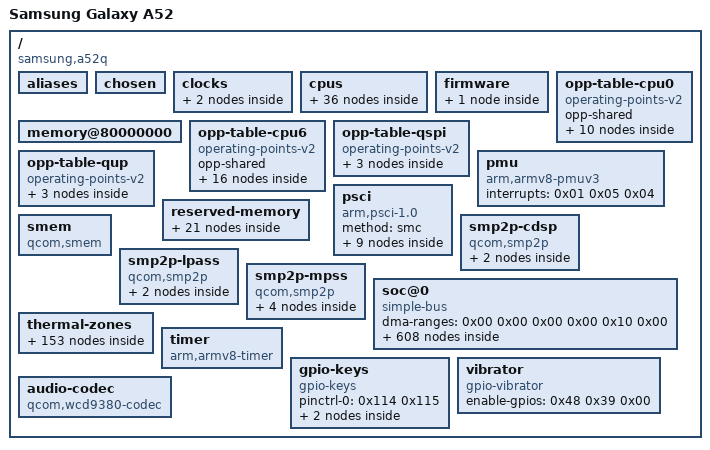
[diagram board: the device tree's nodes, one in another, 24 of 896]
/dts-v1/;

/ {
	interrupt-parent = <0x01>;
	#address-cells = <0x02>;
	#size-cells = <0x02>;
	chassis-type = "handset";
	qcom,msm-id = <0x1bb 0x00>;
	model = "Samsung Galaxy A52";
	compatible = "samsung,a52q", "qcom,sm7125";
	qcom,board-id = <0x22 0x06>;

	aliases {
		mmc1 = "/soc@0/mmc@7c4000";
		mmc2 = "/soc@0/mmc@8804000";
		i2c0 = "/soc@0/geniqup@8c0000/i2c@880000";
		i2c1 = "/soc@0/geniqup@8c0000/i2c@884000";
		i2c2 = "/soc@0/geniqup@8c0000/i2c@888000";
		i2c3 = "/soc@0/geniqup@8c0000/i2c@88c000";
		i2c4 = "/soc@0/geniqup@8c0000/i2c@890000";
		i2c5 = "/soc@0/geniqup@8c0000/i2c@894000";
		i2c6 = "/soc@0/geniqup@ac0000/i2c@a80000";
		i2c7 = "/soc@0/geniqup@ac0000/i2c@a84000";
		i2c8 = "/soc@0/geniqup@ac0000/i2c@a88000";
		i2c9 = "/soc@0/geniqup@ac0000/i2c@a8c000";
		i2c10 = "/soc@0/geniqup@ac0000/i2c@a90000";
		i2c11 = "/soc@0/geniqup@ac0000/i2c@a94000";
		spi0 = "/soc@0/geniqup@8c0000/spi@880000";
		spi1 = "/soc@0/geniqup@8c0000/spi@884000";
		spi3 = "/soc@0/geniqup@8c0000/spi@88c000";
		spi5 = "/soc@0/geniqup@8c0000/spi@894000";
		spi6 = "/soc@0/geniqup@ac0000/spi@a80000";
		spi8 = "/soc@0/geniqup@ac0000/spi@a88000";
		spi10 = "/soc@0/geniqup@ac0000/spi@a90000";
		spi11 = "/soc@0/geniqup@ac0000/spi@a94000";
		bluetooth0 = "/soc@0/geniqup@8c0000/serial@88c000/bluetooth";
		hsuart0 = "/soc@0/geniqup@8c0000/serial@88c000";
		i2c18 = "/soc@0/i2c-18";
		wifi0 = "/soc@0/wifi@18800000";
	};

	chosen {
		linux,initrd-end = <0x00 0xa91fea74>;
		linux,initrd-start = <0x00 0xa8ac4000>;
		kaslr-seed = <0x00 0x00>;
		bootargs = "console=null  pmos_boot_uuid=f75bd1ed-f519-480b-bffc-14573b47cbfd pmos_root_uuid=bdbc92a1-11d9-4b12-ba1a-d4a6c2b9d2fc pmos_rootfsopts=defaults androidboot.verifiedbootstate=orange androidboot.keymaster=1  androidboot.ulcnt=1  androidboot.bootdevice=1d84000.ufshc androidboot.fstab_suffix=default androidboot.boot_devices=soc/1d84000.ufshc androidboot.serialno=R58R31VW3YP androidboot.baseband=msm msm_drm.dsi_display0=ss_dsi_panel_S6E3FC3_AMS646YD04_FHD: lcd_id=0x80000A window_color= androidboot.dtb_idx=-1347440721 androidboot.sec_atd.tty=/dev/ttyHS8 androidboot.revision=8 androidboot.subpcb=3 androidboot.ap_serial=0xB2266249 ccic_info=1 fg_reset=0 sec_log=0x200000@0xB4900000 sec_dbg=0x1FF000@0xB4700000 androidboot.debug_level=0x4f4c sec_debug.enable=0 sec_debug.enable_user=0 msm_rtb.enable=0 androidboot.cp_debug_level=0x55FF sec_debug.enable_cp_debug=0 softdog.soft_margin=100 softdog.soft_panic=1 androidboot.cp_reserved_mem=off androidboot.reserve_mem_region=0x0 androidboot.force_upload=0x0 androidboot.upload_offset=9438196 sec_debug.dump_sink=0x0 signoff=0x7277 androidboot.boot_recovery=0 androidboot.carrierid.param.offset=9437644 androidboot.carrierid=EUX androidboot.sales.param.offset=9437648 androidboot.sales_code=EUX androidboot.prototype.param.offset=9437660 androidboot.im.param.offset=9437232 androidboot.me.param.offset=9437312 androidboot.sn.param.offset=9437392 androidboot.pr.param.offset=9437472 androidboot.sku.param.offset=9437552 androidboot.kg=0x1 androidboot.kg.bit=00 androidboot.kg.ap=AAAA00000000000000000000B2266249 androidboot.fastbootd=false androidboot.warranty_bit=1 androidboot.wb.hs=E02 androidboot.wb.snapQB=64747451R androidboot.ucs_mode=0 androidboot.swp_config=0 androidboot.rp=6 androidboot.svb.ver=SVB1.0 androidboot.em.did=207010B226624911 androidboot.em.model=SM-A525F androidboot.em.status=0x0 androidboot.sb.debug0=0x0 androidboot.em.rdx_dump=false androidboot.bootloader=A525FXXU6FXD2 afc_disable=0x31 sapa=0 androidboot.hdm_status=NONE androidboot.dram_info=01,07,01,6G androidboot.usrf=9438192 factory_mode=0 androidboot.product.model=SM-A525F androidboot.hardware.sku=unknown";
	};

	clocks {

		xo-board {
			compatible = "fixed-clock";
			clock-frequency = <0x249f000>;
			#clock-cells = <0x00>;
			phandle = <0xd7>;
		};

		sleep-clk {
			compatible = "fixed-clock";
			clock-frequency = <0x7ffc>;
			#clock-cells = <0x00>;
			phandle = <0x30>;
		};
	};

	cpus {
		#address-cells = <0x02>;
		#size-cells = <0x00>;

		cpu@0 {
			device_type = "cpu";
			compatible = "qcom,kryo465";
			reg = <0x00 0x00>;
			clocks = <0x02 0x00>;
			enable-method = "psci";
			power-domains = <0x03>;
			power-domain-names = "psci";
			capacity-dmips-mhz = <0x19f>;
			dynamic-power-coefficient = <0x89>;
			operating-points-v2 = <0x04>;
			interconnects = <0x05 0x00 0x03 0x06 0x01 0x03 0x07 0x00 0x07 0x01>;
			next-level-cache = <0x08>;
			#cooling-cells = <0x02>;
			qcom,freq-domain = <0x02 0x00>;
			phandle = <0x19>;

			l2-cache {
				compatible = "cache";
				cache-level = <0x02>;
				cache-unified;
				next-level-cache = <0x09>;
				phandle = <0x08>;

				l3-cache {
					compatible = "cache";
					cache-level = <0x03>;
					cache-unified;
					phandle = <0x09>;
				};
			};
		};

		cpu@100 {
			device_type = "cpu";
			compatible = "qcom,kryo465";
			reg = <0x00 0x100>;
			clocks = <0x02 0x00>;
			enable-method = "psci";
			power-domains = <0x0a>;
			power-domain-names = "psci";
			capacity-dmips-mhz = <0x19f>;
			dynamic-power-coefficient = <0x89>;
			next-level-cache = <0x0b>;
			operating-points-v2 = <0x04>;
			interconnects = <0x05 0x00 0x03 0x06 0x01 0x03 0x07 0x00 0x07 0x01>;
			#cooling-cells = <0x02>;
			qcom,freq-domain = <0x02 0x00>;
			phandle = <0x1a>;

			l2-cache {
				compatible = "cache";
				cache-level = <0x02>;
				cache-unified;
				next-level-cache = <0x09>;
				phandle = <0x0b>;
			};
		};

		cpu@200 {
			device_type = "cpu";
			compatible = "qcom,kryo465";
			reg = <0x00 0x200>;
			clocks = <0x02 0x00>;
			enable-method = "psci";
			power-domains = <0x0c>;
			power-domain-names = "psci";
			capacity-dmips-mhz = <0x19f>;
			dynamic-power-coefficient = <0x89>;
			next-level-cache = <0x0d>;
			operating-points-v2 = <0x04>;
			interconnects = <0x05 0x00 0x03 0x06 0x01 0x03 0x07 0x00 0x07 0x01>;
			#cooling-cells = <0x02>;
			qcom,freq-domain = <0x02 0x00>;
			phandle = <0x1b>;

			l2-cache {
				compatible = "cache";
				cache-level = <0x02>;
				cache-unified;
				next-level-cache = <0x09>;
				phandle = <0x0d>;
			};
		};

		cpu@300 {
			device_type = "cpu";
			compatible = "qcom,kryo465";
			reg = <0x00 0x300>;
			clocks = <0x02 0x00>;
			enable-method = "psci";
			power-domains = <0x0e>;
			power-domain-names = "psci";
			capacity-dmips-mhz = <0x19f>;
			dynamic-power-coefficient = <0x89>;
			next-level-cache = <0x0f>;
			operating-points-v2 = <0x04>;
			interconnects = <0x05 0x00 0x03 0x06 0x01 0x03 0x07 0x00 0x07 0x01>;
			#cooling-cells = <0x02>;
			qcom,freq-domain = <0x02 0x00>;
			phandle = <0x1c>;

			l2-cache {
				compatible = "cache";
				cache-level = <0x02>;
				cache-unified;
				next-level-cache = <0x09>;
				phandle = <0x0f>;
			};
		};

		cpu@400 {
			device_type = "cpu";
			compatible = "qcom,kryo465";
			reg = <0x00 0x400>;
			clocks = <0x02 0x00>;
			enable-method = "psci";
			power-domains = <0x10>;
			power-domain-names = "psci";
			capacity-dmips-mhz = <0x19f>;
			dynamic-power-coefficient = <0x89>;
			next-level-cache = <0x11>;
			operating-points-v2 = <0x04>;
			interconnects = <0x05 0x00 0x03 0x06 0x01 0x03 0x07 0x00 0x07 0x01>;
			#cooling-cells = <0x02>;
			qcom,freq-domain = <0x02 0x00>;
			phandle = <0x1d>;

			l2-cache {
				compatible = "cache";
				cache-level = <0x02>;
				cache-unified;
				next-level-cache = <0x09>;
				phandle = <0x11>;
			};
		};

		cpu@500 {
			device_type = "cpu";
			compatible = "qcom,kryo465";
			reg = <0x00 0x500>;
			clocks = <0x02 0x00>;
			enable-method = "psci";
			power-domains = <0x12>;
			power-domain-names = "psci";
			capacity-dmips-mhz = <0x19f>;
			dynamic-power-coefficient = <0x89>;
			next-level-cache = <0x13>;
			operating-points-v2 = <0x04>;
			interconnects = <0x05 0x00 0x03 0x06 0x01 0x03 0x07 0x00 0x07 0x01>;
			#cooling-cells = <0x02>;
			qcom,freq-domain = <0x02 0x00>;
			phandle = <0x1e>;

			l2-cache {
				compatible = "cache";
				cache-level = <0x02>;
				cache-unified;
				next-level-cache = <0x09>;
				phandle = <0x13>;
			};
		};

		cpu@600 {
			device_type = "cpu";
			compatible = "qcom,kryo465";
			reg = <0x00 0x600>;
			clocks = <0x02 0x01>;
			enable-method = "psci";
			power-domains = <0x14>;
			power-domain-names = "psci";
			capacity-dmips-mhz = <0x400>;
			dynamic-power-coefficient = <0x1e0>;
			next-level-cache = <0x15>;
			operating-points-v2 = <0x16>;
			interconnects = <0x05 0x00 0x03 0x06 0x01 0x03 0x07 0x00 0x07 0x01>;
			#cooling-cells = <0x02>;
			qcom,freq-domain = <0x02 0x01>;
			phandle = <0x1f>;

			l2-cache {
				compatible = "cache";
				cache-level = <0x02>;
				cache-unified;
				next-level-cache = <0x09>;
				phandle = <0x15>;
			};
		};

		cpu@700 {
			device_type = "cpu";
			compatible = "qcom,kryo465";
			reg = <0x00 0x700>;
			clocks = <0x02 0x01>;
			enable-method = "psci";
			power-domains = <0x17>;
			power-domain-names = "psci";
			capacity-dmips-mhz = <0x400>;
			dynamic-power-coefficient = <0x1e0>;
			next-level-cache = <0x18>;
			operating-points-v2 = <0x16>;
			interconnects = <0x05 0x00 0x03 0x06 0x01 0x03 0x07 0x00 0x07 0x01>;
			#cooling-cells = <0x02>;
			qcom,freq-domain = <0x02 0x01>;
			phandle = <0x20>;

			l2-cache {
				compatible = "cache";
				cache-level = <0x02>;
				cache-unified;
				next-level-cache = <0x09>;
				phandle = <0x18>;
			};
		};

		cpu-map {

			cluster0 {

				core0 {
					cpu = <0x19>;
				};

				core1 {
					cpu = <0x1a>;
				};

				core2 {
					cpu = <0x1b>;
				};

				core3 {
					cpu = <0x1c>;
				};

				core4 {
					cpu = <0x1d>;
				};

				core5 {
					cpu = <0x1e>;
				};

				core6 {
					cpu = <0x1f>;
				};

				core7 {
					cpu = <0x20>;
				};
			};
		};

		idle-states {
			entry-method = "psci";

			cpu-sleep-0-0 {
				compatible = "arm,idle-state";
				idle-state-name = "little-power-down";
				arm,psci-suspend-param = <0x40000003>;
				entry-latency-us = <0x225>;
				exit-latency-us = <0x385>;
				min-residency-us = <0x6ee>;
				local-timer-stop;
				phandle = <0x25>;
			};

			cpu-sleep-0-1 {
				compatible = "arm,idle-state";
				idle-state-name = "little-rail-power-down";
				arm,psci-suspend-param = <0x40000004>;
				entry-latency-us = <0x2be>;
				exit-latency-us = <0x393>;
				min-residency-us = <0xfa1>;
				local-timer-stop;
				phandle = <0x26>;
			};

			cpu-sleep-1-0 {
				compatible = "arm,idle-state";
				idle-state-name = "big-power-down";
				arm,psci-suspend-param = <0x40000003>;
				entry-latency-us = <0x20b>;
				exit-latency-us = <0x4dc>;
				min-residency-us = <0x89f>;
				local-timer-stop;
				phandle = <0x27>;
			};

			cpu-sleep-1-1 {
				compatible = "arm,idle-state";
				idle-state-name = "big-rail-power-down";
				arm,psci-suspend-param = <0x40000004>;
				entry-latency-us = <0x20e>;
				exit-latency-us = <0x73e>;
				min-residency-us = <0x15b3>;
				local-timer-stop;
				phandle = <0x28>;
			};
		};

		domain-idle-states {

			cluster-sleep-0 {
				compatible = "domain-idle-state";
				idle-state-name = "cluster-l3-power-collapse";
				arm,psci-suspend-param = <0x41000044>;
				entry-latency-us = <0xac0>;
				exit-latency-us = <0xbe8>;
				min-residency-us = <0x17e6>;
				phandle = <0x29>;
			};

			cluster-sleep-1 {
				compatible = "domain-idle-state";
				idle-state-name = "cluster-cx-retention";
				arm,psci-suspend-param = <0x41001244>;
				entry-latency-us = <0xe36>;
				exit-latency-us = <0x11d2>;
				min-residency-us = <0x2113>;
				phandle = <0x2a>;
			};

			cluster-sleep-2 {
				compatible = "domain-idle-state";
				idle-state-name = "cluster-power-down";
				arm,psci-suspend-param = <0x4100b244>;
				entry-latency-us = <0xcbf>;
				exit-latency-us = <0x19a2>;
				min-residency-us = <0x2662>;
				phandle = <0x2b>;
			};
		};
	};

	firmware {

		scm {
			compatible = "qcom,scm-sc7180", "qcom,scm";
		};
	};

	memory@80000000 {
		ddr_device_type = <0x07>;
		device_type = "memory";
		reg = <0x00 0x80000000 0x00 0x3cc00000 0x01 0x00 0x01 0x00 0x00 0xc0000000 0x00 0x40000000>;
	};

	opp-table-cpu0 {
		compatible = "operating-points-v2";
		opp-shared;
		phandle = <0x04>;

		opp-300000000 {
			opp-hz = <0x00 0x11e1a300>;
			opp-peak-kBps = <0x124f80 0x493e00>;
		};

		opp-576000000 {
			opp-hz = <0x00 0x22551000>;
			opp-peak-kBps = <0x124f80 0x493e00>;
		};

		opp-768000000 {
			opp-hz = <0x00 0x2dc6c000>;
			opp-peak-kBps = <0x124f80 0x493e00>;
		};

		opp-1017600000 {
			opp-hz = <0x00 0x3ca75800>;
			opp-peak-kBps = <0x1b86e0 0x87f000>;
		};

		opp-1248000000 {
			opp-hz = <0x00 0x4a62f800>;
			opp-peak-kBps = <0x2162e0 0xc4e000>;
		};

		opp-1324800000 {
			opp-hz = <0x00 0x4ef6d800>;
			opp-peak-kBps = <0x2162e0 0xc4e000>;
		};

		opp-1516800000 {
			opp-hz = <0x00 0x5a688800>;
			opp-peak-kBps = <0x2ee000 0xe5b000>;
		};

		opp-1612800000 {
			opp-hz = <0x00 0x60216000>;
			opp-peak-kBps = <0x2ee000 0xe5b000>;
		};

		opp-1708800000 {
			opp-hz = <0x00 0x65da3800>;
			opp-peak-kBps = <0x2ee000 0xe5b000>;
		};

		opp-1804800000 {
			opp-hz = <0x00 0x6b931000>;
			opp-peak-kBps = <0x3e12a0 0x1563000>;
		};
	};

	opp-table-cpu6 {
		compatible = "operating-points-v2";
		opp-shared;
		phandle = <0x16>;

		opp-300000000 {
			opp-hz = <0x00 0x11e1a300>;
			opp-peak-kBps = <0x2162e0 0x87f000>;
		};

		opp-652800000 {
			opp-hz = <0x00 0x26e8f000>;
			opp-peak-kBps = <0x2162e0 0x87f000>;
		};

		opp-825600000 {
			opp-hz = <0x00 0x3135a800>;
			opp-peak-kBps = <0x2162e0 0x87f000>;
		};

		opp-979200000 {
			opp-hz = <0x00 0x3a5d6800>;
			opp-peak-kBps = <0x2162e0 0x87f000>;
		};

		opp-1113600000 {
			opp-hz = <0x00 0x42603000>;
			opp-peak-kBps = <0x2162e0 0x87f000>;
		};

		opp-1267200000 {
			opp-hz = <0x00 0x4b87f000>;
			opp-peak-kBps = <0x3e12a0 0xc4e000>;
		};

		opp-1555200000 {
			opp-hz = <0x00 0x5cb27800>;
			opp-peak-kBps = <0x3e12a0 0xe5b000>;
		};

		opp-1708800000 {
			opp-hz = <0x00 0x65da3800>;
			opp-peak-kBps = <0x5ee8e0 0x1275000>;
		};

		opp-1843200000 {
			opp-hz = <0x00 0x6ddd0000>;
			opp-peak-kBps = <0x5ee8e0 0x1275000>;
		};

		opp-1900800000 {
			opp-hz = <0x00 0x714be800>;
			opp-peak-kBps = <0x5ee8e0 0x1563000>;
		};

		opp-1996800000 {
			opp-hz = <0x00 0x7704c000>;
			opp-peak-kBps = <0x5ee8e0 0x1563000>;
		};

		opp-2112000000 {
			opp-hz = <0x00 0x7de29000>;
			opp-peak-kBps = <0x5ee8e0 0x1563000>;
		};

		opp-2208000000 {
			opp-hz = <0x00 0x839b6800>;
			opp-peak-kBps = <0x6e1b80 0x1563000>;
		};

		opp-2323200000 {
			opp-hz = <0x00 0x8a793800>;
			opp-peak-kBps = <0x6e1b80 0x1563000>;
		};

		opp-2400000000 {
			opp-hz = <0x00 0x8f0d1800>;
			opp-peak-kBps = <0x823020 0x1644000>;
		};

		opp-2553600000 {
			opp-hz = <0x00 0x9834d800>;
			opp-peak-kBps = <0x823020 0x1644000>;
		};
	};

	opp-table-qspi {
		compatible = "operating-points-v2";
		phandle = <0xad>;

		opp-75000000 {
			opp-hz = <0x00 0x47868c0>;
			required-opps = <0x21>;
		};

		opp-150000000 {
			opp-hz = <0x00 0x8f0d180>;
			required-opps = <0x22>;
		};

		opp-300000000 {
			opp-hz = <0x00 0x11e1a300>;
			required-opps = <0x23>;
		};
	};

	opp-table-qup {
		compatible = "operating-points-v2";
		phandle = <0x3c>;

		opp-75000000 {
			opp-hz = <0x00 0x47868c0>;
			required-opps = <0x21>;
		};

		opp-100000000 {
			opp-hz = <0x00 0x5f5e100>;
			required-opps = <0x22>;
		};

		opp-128000000 {
			opp-hz = <0x00 0x7a12000>;
			required-opps = <0x23>;
		};
	};

	pmu {
		compatible = "arm,armv8-pmuv3";
		interrupts = <0x01 0x05 0x04>;
	};

	psci {
		compatible = "arm,psci-1.0";
		method = "smc";

		cpu0 {
			#power-domain-cells = <0x00>;
			power-domains = <0x24>;
			domain-idle-states = <0x25 0x26>;
			phandle = <0x03>;
		};

		cpu1 {
			#power-domain-cells = <0x00>;
			power-domains = <0x24>;
			domain-idle-states = <0x25 0x26>;
			phandle = <0x0a>;
		};

		cpu2 {
			#power-domain-cells = <0x00>;
			power-domains = <0x24>;
			domain-idle-states = <0x25 0x26>;
			phandle = <0x0c>;
		};

		cpu3 {
			#power-domain-cells = <0x00>;
			power-domains = <0x24>;
			domain-idle-states = <0x25 0x26>;
			phandle = <0x0e>;
		};

		cpu4 {
			#power-domain-cells = <0x00>;
			power-domains = <0x24>;
			domain-idle-states = <0x25 0x26>;
			phandle = <0x10>;
		};

		cpu5 {
			#power-domain-cells = <0x00>;
			power-domains = <0x24>;
			domain-idle-states = <0x25 0x26>;
			phandle = <0x12>;
		};

		cpu6 {
			#power-domain-cells = <0x00>;
			power-domains = <0x24>;
			domain-idle-states = <0x27 0x28>;
			phandle = <0x14>;
		};

		cpu7 {
			#power-domain-cells = <0x00>;
			power-domains = <0x24>;
			domain-idle-states = <0x27 0x28>;
			phandle = <0x17>;
		};

		cpu-cluster0 {
			#power-domain-cells = <0x00>;
			domain-idle-states = <0x29 0x2a 0x2b>;
			phandle = <0x24>;
		};
	};

	reserved-memory {
		#address-cells = <0x02>;
		#size-cells = <0x02>;
		ranges;

		uh_heap_region {
			reg = <0x00 0xb0400000 0x00 0x1400000>;
		};

		memory@80000000 {
			reg = <0x00 0x80000000 0x00 0x600000>;
			no-map;
		};

		memory@80600000 {
			reg = <0x00 0x80600000 0x00 0x200000>;
			no-map;
		};

		memory@80800000 {
			reg = <0x00 0x80800000 0x00 0x20000>;
			no-map;
		};

		memory@80820000 {
			reg = <0x00 0x80820000 0x00 0x20000>;
			compatible = "qcom,cmd-db";
			no-map;
		};

		memory@808ff000 {
			reg = <0x00 0x808ff000 0x00 0x1000>;
			no-map;
		};

		memory@80900000 {
			reg = <0x00 0x80900000 0x00 0x200000>;
			no-map;
			phandle = <0x2c>;
		};

		memory@80b00000 {
			reg = <0x00 0x80b00000 0x00 0x7100000>;
			no-map;
		};

		memory@8b000000 {
			reg = <0x00 0x8b000000 0x00 0x8900000>;
			no-map;
			phandle = <0x7b>;
		};

		memory@93900000 {
			reg = <0x00 0x93900000 0x00 0x200000>;
			no-map;
			phandle = <0xd9>;
		};

		memory@93b00000 {
			reg = <0x00 0x93b00000 0x00 0x10000>;
			no-map;
			phandle = <0x78>;
		};

		memory@93b10000 {
			reg = <0x00 0x93b10000 0x00 0x5000>;
			no-map;
		};

		memory@93b15000 {
			reg = <0x00 0x93b15000 0x00 0x2000>;
			no-map;
			phandle = <0x81>;
		};

		memory@93c00000 {
			reg = <0x00 0x93c00000 0x00 0x3e00000>;
			no-map;
			phandle = <0xde>;
		};

		memory@97a00000 {
			reg = <0x00 0x97a00000 0x00 0x500000>;
			no-map;
		};

		memory@97f00000 {
			reg = <0x00 0x97f00000 0x00 0x500000>;
			no-map;
		};

		memory@98400000 {
			reg = <0x00 0x98400000 0x00 0x500000>;
			no-map;
			phandle = <0xb6>;
		};

		memory@98900000 {
			reg = <0x00 0x98900000 0x00 0x1e00000>;
			no-map;
			phandle = <0xf6>;
		};

		memory@9e000000 {
			reg = <0x00 0x9e000000 0x00 0x2000000>;
			no-map;
		};

		ramoops@b4600000 {
			compatible = "ramoops";
			reg = <0x00 0xb4600000 0x00 0x100000>;
			record-size = <0x40000>;
			console-size = <0x40000>;
			ftrace-size = <0x40000>;
			pmsg-size = <0x40000>;
		};

		memory@f4f01000 {
			compatible = "qcom,rmtfs-mem";
			reg = <0x00 0xf4f01000 0x00 0x200000>;
			no-map;
			qcom,client-id = <0x01>;
			qcom,vmid = <0x0f>;
		};
	};

	smem {
		compatible = "qcom,smem";
		memory-region = <0x2c>;
		hwlocks = <0x2d 0x03>;
	};

	smp2p-cdsp {
		compatible = "qcom,smp2p";
		qcom,smem = <0x5e 0x1b0>;
		interrupts = <0x00 0x240 0x01>;
		mboxes = <0x2e 0x06>;
		qcom,local-pid = <0x00>;
		qcom,remote-pid = <0x05>;

		master-kernel {
			qcom,entry-name = "master-kernel";
			#qcom,smem-state-cells = <0x01>;
			phandle = <0xf7>;
		};

		slave-kernel {
			qcom,entry-name = "slave-kernel";
			interrupt-controller;
			#interrupt-cells = <0x02>;
			phandle = <0xf5>;
		};
	};

	smp2p-lpass {
		compatible = "qcom,smp2p";
		qcom,smem = <0x1bb 0x1ad>;
		interrupts = <0x00 0x9e 0x01>;
		mboxes = <0x2e 0x0a>;
		qcom,local-pid = <0x00>;
		qcom,remote-pid = <0x02>;

		master-kernel {
			qcom,entry-name = "master-kernel";
			#qcom,smem-state-cells = <0x01>;
			phandle = <0xdd>;
		};

		slave-kernel {
			qcom,entry-name = "slave-kernel";
			interrupt-controller;
			#interrupt-cells = <0x02>;
			phandle = <0xdc>;
		};
	};

	smp2p-mpss {
		compatible = "qcom,smp2p";
		qcom,smem = <0x1b3 0x1ac>;
		interrupts = <0x00 0x1c3 0x01>;
		mboxes = <0x2e 0x0e>;
		qcom,local-pid = <0x00>;
		qcom,remote-pid = <0x01>;

		master-kernel {
			qcom,entry-name = "master-kernel";
			#qcom,smem-state-cells = <0x01>;
			phandle = <0x7c>;
		};

		slave-kernel {
			qcom,entry-name = "slave-kernel";
			interrupt-controller;
			#interrupt-cells = <0x02>;
			phandle = <0x7a>;
		};

		ipa-ap-to-modem {
			qcom,entry-name = "ipa";
			#qcom,smem-state-cells = <0x01>;
			phandle = <0x77>;
		};

		ipa-modem-to-ap {
			qcom,entry-name = "ipa";
			interrupt-controller;
			#interrupt-cells = <0x02>;
			phandle = <0x74>;
		};
	};

	soc@0 {
		#address-cells = <0x02>;
		#size-cells = <0x02>;
		ranges = <0x00 0x00 0x00 0x00 0x10 0x00>;
		dma-ranges = <0x00 0x00 0x00 0x00 0x10 0x00>;
		compatible = "simple-bus";

		sec_hw_param {
			param0 = <0x01 0x32f>;
		};

		clock-controller@100000 {
			compatible = "qcom,gcc-sc7180";
			reg = <0x00 0x100000 0x00 0x1f0000>;
			clocks = <0x2f 0x00 0x2f 0x01 0x30>;
			clock-names = "bi_tcxo", "bi_tcxo_ao", "sleep_clk";
			#clock-cells = <0x01>;
			#reset-cells = <0x01>;
			#power-domain-cells = <0x01>;
			power-domains = <0x31 0x00>;
			phandle = <0x32>;
		};

		efuse@784000 {
			compatible = "qcom,sc7180-qfprom", "qcom,qfprom";
			reg = <0x00 0x784000 0x00 0x7a0 0x00 0x780000 0x00 0x7a0 0x00 0x782000 0x00 0x100 0x00 0x786000 0x00 0x1fff>;
			clocks = <0x32 0x82>;
			clock-names = "core";
			#address-cells = <0x01>;
			#size-cells = <0x01>;
			vcc-supply = <0x33>;

			hstx-trim-primary@25b {
				reg = <0x25b 0x01>;
				bits = <0x01 0x03>;
				phandle = <0xae>;
			};

			gpu-speed-bin@1d2 {
				reg = <0x1d2 0x02>;
				bits = <0x05 0x08>;
				phandle = <0x80>;
			};
		};

		mmc@7c4000 {
			compatible = "qcom,sc7180-sdhci", "qcom,sdhci-msm-v5";
			reg = <0x00 0x7c4000 0x00 0x1000 0x00 0x7c5000 0x00 0x1000>;
			reg-names = "hc", "cqhci";
			iommus = <0x34 0x60 0x00>;
			interrupts = <0x00 0x281 0x04 0x00 0x284 0x04>;
			interrupt-names = "hc_irq", "pwr_irq";
			clocks = <0x32 0x58 0x32 0x59 0x2f 0x00>;
			clock-names = "iface", "core", "xo";
			interconnects = <0x35 0x04 0x00 0x06 0x01 0x00 0x05 0x00 0x00 0x36 0x15 0x00>;
			interconnect-names = "sdhc-ddr", "cpu-sdhc";
			power-domains = <0x31 0x00>;
			operating-points-v2 = <0x37>;
			bus-width = <0x08>;
			non-removable;
			supports-cqe;
			mmc-ddr-1_8v;
			mmc-hs200-1_8v;
			mmc-hs400-1_8v;
			mmc-hs400-enhanced-strobe;
			status = "disabled";

			opp-table {
				compatible = "operating-points-v2";
				phandle = <0x37>;

				opp-100000000 {
					opp-hz = <0x00 0x5f5e100>;
					required-opps = <0x21>;
					opp-peak-kBps = <0x1b7740 0x927c0>;
					opp-avg-kBps = <0x186a0 0x00>;
				};

				opp-384000000 {
					opp-hz = <0x00 0x16e36000>;
					required-opps = <0x23>;
					opp-peak-kBps = <0x5265c0 0x186a00>;
					opp-avg-kBps = <0x5f370 0x00>;
				};
			};
		};

		geniqup@8c0000 {
			compatible = "qcom,geni-se-qup";
			reg = <0x00 0x8c0000 0x00 0x6000>;
			clock-names = "m-ahb", "s-ahb";
			clocks = <0x32 0x54 0x32 0x55>;
			#address-cells = <0x02>;
			#size-cells = <0x02>;
			ranges;
			iommus = <0x34 0x43 0x00>;
			status = "okay";

			i2c@880000 {
				compatible = "qcom,geni-i2c";
				reg = <0x00 0x880000 0x00 0x4000>;
				clock-names = "se";
				clocks = <0x32 0x3a>;
				pinctrl-names = "default";
				pinctrl-0 = <0x38>;
				interrupts = <0x00 0x259 0x04>;
				#address-cells = <0x01>;
				#size-cells = <0x00>;
				interconnects = <0x39 0x00 0x00 0x39 0x02 0x00 0x05 0x00 0x00 0x36 0x26 0x00 0x35 0x02 0x00 0x06 0x01 0x00>;
				interconnect-names = "qup-core", "qup-config", "qup-memory";
				power-domains = <0x31 0x00>;
				required-opps = <0x21>;
				status = "disabled";
			};

			spi@880000 {
				compatible = "qcom,geni-spi";
				reg = <0x00 0x880000 0x00 0x4000>;
				clock-names = "se";
				clocks = <0x32 0x3a>;
				pinctrl-names = "default";
				pinctrl-0 = <0x3a 0x3b>;
				interrupts = <0x00 0x259 0x04>;
				#address-cells = <0x01>;
				#size-cells = <0x00>;
				power-domains = <0x31 0x00>;
				operating-points-v2 = <0x3c>;
				interconnects = <0x39 0x00 0x00 0x39 0x02 0x00 0x05 0x00 0x00 0x36 0x26 0x00>;
				interconnect-names = "qup-core", "qup-config";
				status = "disabled";
			};

			serial@880000 {
				compatible = "qcom,geni-uart";
				reg = <0x00 0x880000 0x00 0x4000>;
				clock-names = "se";
				clocks = <0x32 0x3a>;
				pinctrl-names = "default";
				pinctrl-0 = <0x3d>;
				interrupts = <0x00 0x259 0x04>;
				power-domains = <0x31 0x00>;
				operating-points-v2 = <0x3c>;
				interconnects = <0x39 0x00 0x00 0x39 0x02 0x00 0x05 0x00 0x00 0x36 0x26 0x00>;
				interconnect-names = "qup-core", "qup-config";
				status = "disabled";
			};

			i2c@884000 {
				compatible = "qcom,geni-i2c";
				reg = <0x00 0x884000 0x00 0x4000>;
				clock-names = "se";
				clocks = <0x32 0x3c>;
				pinctrl-names = "default";
				pinctrl-0 = <0x3e>;
				interrupts = <0x00 0x25a 0x04>;
				#address-cells = <0x01>;
				#size-cells = <0x00>;
				interconnects = <0x39 0x00 0x00 0x39 0x02 0x00 0x05 0x00 0x00 0x36 0x26 0x00 0x35 0x02 0x00 0x06 0x01 0x00>;
				interconnect-names = "qup-core", "qup-config", "qup-memory";
				power-domains = <0x31 0x00>;
				required-opps = <0x21>;
				status = "disabled";
			};

			spi@884000 {
				compatible = "qcom,geni-spi";
				reg = <0x00 0x884000 0x00 0x4000>;
				clock-names = "se";
				clocks = <0x32 0x3c>;
				pinctrl-names = "default";
				pinctrl-0 = <0x3f 0x40>;
				interrupts = <0x00 0x25a 0x04>;
				#address-cells = <0x01>;
				#size-cells = <0x00>;
				power-domains = <0x31 0x00>;
				operating-points-v2 = <0x3c>;
				interconnects = <0x39 0x00 0x00 0x39 0x02 0x00 0x05 0x00 0x00 0x36 0x26 0x00>;
				interconnect-names = "qup-core", "qup-config";
				status = "disabled";
			};

			serial@884000 {
				compatible = "qcom,geni-uart";
				reg = <0x00 0x884000 0x00 0x4000>;
				clock-names = "se";
				clocks = <0x32 0x3c>;
				pinctrl-names = "default";
				pinctrl-0 = <0x41>;
				interrupts = <0x00 0x25a 0x04>;
				power-domains = <0x31 0x00>;
				operating-points-v2 = <0x3c>;
				interconnects = <0x39 0x00 0x00 0x39 0x02 0x00 0x05 0x00 0x00 0x36 0x26 0x00>;
				interconnect-names = "qup-core", "qup-config";
				status = "disabled";
			};

			i2c@888000 {
				compatible = "qcom,geni-i2c";
				reg = <0x00 0x888000 0x00 0x4000>;
				clock-names = "se";
				clocks = <0x32 0x3e>;
				pinctrl-names = "default";
				pinctrl-0 = <0x42>;
				interrupts = <0x00 0x25b 0x04>;
				#address-cells = <0x01>;
				#size-cells = <0x00>;
				interconnects = <0x39 0x00 0x00 0x39 0x02 0x00 0x05 0x00 0x00 0x36 0x26 0x00 0x35 0x02 0x00 0x06 0x01 0x00>;
				interconnect-names = "qup-core", "qup-config", "qup-memory";
				power-domains = <0x31 0x00>;
				required-opps = <0x21>;
				status = "disabled";
			};

			serial@888000 {
				compatible = "qcom,geni-uart";
				reg = <0x00 0x888000 0x00 0x4000>;
				clock-names = "se";
				clocks = <0x32 0x3e>;
				pinctrl-names = "default";
				pinctrl-0 = <0x43>;
				interrupts = <0x00 0x25b 0x04>;
				power-domains = <0x31 0x00>;
				operating-points-v2 = <0x3c>;
				interconnects = <0x39 0x00 0x00 0x39 0x02 0x00 0x05 0x00 0x00 0x36 0x26 0x00>;
				interconnect-names = "qup-core", "qup-config";
				status = "disabled";
			};

			i2c@88c000 {
				compatible = "qcom,geni-i2c";
				reg = <0x00 0x88c000 0x00 0x4000>;
				clock-names = "se";
				clocks = <0x32 0x40>;
				pinctrl-names = "default";
				pinctrl-0 = <0x44>;
				interrupts = <0x00 0x25c 0x04>;
				#address-cells = <0x01>;
				#size-cells = <0x00>;
				interconnects = <0x39 0x00 0x00 0x39 0x02 0x00 0x05 0x00 0x00 0x36 0x26 0x00 0x35 0x02 0x00 0x06 0x01 0x00>;
				interconnect-names = "qup-core", "qup-config", "qup-memory";
				power-domains = <0x31 0x00>;
				required-opps = <0x21>;
				status = "disabled";
			};

			spi@88c000 {
				compatible = "qcom,geni-spi";
				reg = <0x00 0x88c000 0x00 0x4000>;
				clock-names = "se";
				clocks = <0x32 0x40>;
				pinctrl-names = "default";
				pinctrl-0 = <0x45 0x46>;
				interrupts = <0x00 0x25c 0x04>;
				#address-cells = <0x01>;
				#size-cells = <0x00>;
				power-domains = <0x31 0x00>;
				operating-points-v2 = <0x3c>;
				interconnects = <0x39 0x00 0x00 0x39 0x02 0x00 0x05 0x00 0x00 0x36 0x26 0x00>;
				interconnect-names = "qup-core", "qup-config";
				status = "disabled";
			};

			serial@88c000 {
				compatible = "qcom,geni-uart";
				reg = <0x00 0x88c000 0x00 0x4000>;
				clock-names = "se";
				clocks = <0x32 0x40>;
				pinctrl-names = "default", "sleep";
				pinctrl-0 = <0x47>;
				power-domains = <0x31 0x00>;
				operating-points-v2 = <0x3c>;
				interconnects = <0x39 0x00 0x00 0x39 0x02 0x00 0x05 0x00 0x00 0x36 0x26 0x00>;
				interconnect-names = "qup-core", "qup-config";
				status = "okay";
				interrupts-extended = <0x01 0x00 0x25c 0x04 0x48 0x29 0x02>;
				pinctrl-1 = <0x49>;

				bluetooth {
					compatible = "qcom,wcn3988-bt";
					local-bd-address = [22 00 00 00 5a ad];
					vddio-supply = <0x4a>;
					vddxo-supply = <0x4b>;
					vddrf-supply = <0x4c>;
					vddch0-supply = <0x4d>;
					swctrl-gpios = <0x48 0x49 0x00>;
					max-speed = <0x30d400>;
					firmware-name = "sm7125/a52q/apnv11.bin";
				};
			};

			i2c@890000 {
				compatible = "qcom,geni-i2c";
				reg = <0x00 0x890000 0x00 0x4000>;
				clock-names = "se";
				clocks = <0x32 0x42>;
				pinctrl-names = "default";
				pinctrl-0 = <0x4e>;
				interrupts = <0x00 0x25d 0x04>;
				#address-cells = <0x01>;
				#size-cells = <0x00>;
				interconnects = <0x39 0x00 0x00 0x39 0x02 0x00 0x05 0x00 0x00 0x36 0x26 0x00 0x35 0x02 0x00 0x06 0x01 0x00>;
				interconnect-names = "qup-core", "qup-config", "qup-memory";
				power-domains = <0x31 0x00>;
				required-opps = <0x21>;
				status = "okay";

				sm5714-charger@49 {
					compatible = "siliconmitus,sm5714-charger";
					reg = <0x49>;
					siliconmitus,enable-autostop;
					siliconmitus,input-current-limit = <0x514>;
					siliconmitus,charging-current = <0x514>;
					siliconmitus,topoff-current = <0xe1>;
				};

				sm5714-fg@71 {
					compatible = "siliconmitus,sm5714-fg";
					reg = <0x71>;
				};
			};

			serial@890000 {
				compatible = "qcom,geni-uart";
				reg = <0x00 0x890000 0x00 0x4000>;
				clock-names = "se";
				clocks = <0x32 0x42>;
				pinctrl-names = "default";
				pinctrl-0 = <0x4f>;
				interrupts = <0x00 0x25d 0x04>;
				power-domains = <0x31 0x00>;
				operating-points-v2 = <0x3c>;
				interconnects = <0x39 0x00 0x00 0x39 0x02 0x00 0x05 0x00 0x00 0x36 0x26 0x00>;
				interconnect-names = "qup-core", "qup-config";
				status = "disabled";
			};

			i2c@894000 {
				compatible = "qcom,geni-i2c";
				reg = <0x00 0x894000 0x00 0x4000>;
				clock-names = "se";
				clocks = <0x32 0x44>;
				pinctrl-names = "default";
				pinctrl-0 = <0x50>;
				interrupts = <0x00 0x25e 0x04>;
				#address-cells = <0x01>;
				#size-cells = <0x00>;
				interconnects = <0x39 0x00 0x00 0x39 0x02 0x00 0x05 0x00 0x00 0x36 0x26 0x00 0x35 0x02 0x00 0x06 0x01 0x00>;
				interconnect-names = "qup-core", "qup-config", "qup-memory";
				power-domains = <0x31 0x00>;
				required-opps = <0x21>;
				status = "disabled";
			};

			spi@894000 {
				compatible = "qcom,geni-spi";
				reg = <0x00 0x894000 0x00 0x4000>;
				clock-names = "se";
				clocks = <0x32 0x44>;
				pinctrl-names = "default";
				pinctrl-0 = <0x51 0x52>;
				interrupts = <0x00 0x25e 0x04>;
				#address-cells = <0x01>;
				#size-cells = <0x00>;
				power-domains = <0x31 0x00>;
				operating-points-v2 = <0x3c>;
				interconnects = <0x39 0x00 0x00 0x39 0x02 0x00 0x05 0x00 0x00 0x36 0x26 0x00>;
				interconnect-names = "qup-core", "qup-config";
				status = "disabled";
			};

			serial@894000 {
				compatible = "qcom,geni-uart";
				reg = <0x00 0x894000 0x00 0x4000>;
				clock-names = "se";
				clocks = <0x32 0x44>;
				pinctrl-names = "default";
				pinctrl-0 = <0x53>;
				interrupts = <0x00 0x25e 0x04>;
				power-domains = <0x31 0x00>;
				operating-points-v2 = <0x3c>;
				interconnects = <0x39 0x00 0x00 0x39 0x02 0x00 0x05 0x00 0x00 0x36 0x26 0x00>;
				interconnect-names = "qup-core", "qup-config";
				status = "disabled";
			};
		};

		geniqup@ac0000 {
			compatible = "qcom,geni-se-qup";
			reg = <0x00 0xac0000 0x00 0x6000>;
			clock-names = "m-ahb", "s-ahb";
			clocks = <0x32 0x56 0x32 0x57>;
			#address-cells = <0x02>;
			#size-cells = <0x02>;
			ranges;
			iommus = <0x34 0x4c3 0x00>;
			status = "okay";

			i2c@a80000 {
				compatible = "qcom,geni-i2c";
				reg = <0x00 0xa80000 0x00 0x4000>;
				clock-names = "se";
				clocks = <0x32 0x48>;
				pinctrl-names = "default";
				pinctrl-0 = <0x54>;
				interrupts = <0x00 0x161 0x04>;
				#address-cells = <0x01>;
				#size-cells = <0x00>;
				interconnects = <0x39 0x01 0x00 0x39 0x03 0x00 0x05 0x00 0x00 0x36 0x27 0x00 0x55 0x02 0x00 0x06 0x01 0x00>;
				interconnect-names = "qup-core", "qup-config", "qup-memory";
				power-domains = <0x31 0x00>;
				required-opps = <0x21>;
				status = "disabled";
			};

			spi@a80000 {
				compatible = "qcom,geni-spi";
				reg = <0x00 0xa80000 0x00 0x4000>;
				clock-names = "se";
				clocks = <0x32 0x48>;
				pinctrl-names = "default";
				pinctrl-0 = <0x56 0x57>;
				interrupts = <0x00 0x161 0x04>;
				#address-cells = <0x01>;
				#size-cells = <0x00>;
				power-domains = <0x31 0x00>;
				operating-points-v2 = <0x3c>;
				interconnects = <0x39 0x01 0x00 0x39 0x03 0x00 0x05 0x00 0x00 0x36 0x27 0x00>;
				interconnect-names = "qup-core", "qup-config";
				status = "disabled";
			};

			serial@a80000 {
				compatible = "qcom,geni-uart";
				reg = <0x00 0xa80000 0x00 0x4000>;
				clock-names = "se";
				clocks = <0x32 0x48>;
				pinctrl-names = "default";
				pinctrl-0 = <0x58>;
				interrupts = <0x00 0x161 0x04>;
				power-domains = <0x31 0x00>;
				operating-points-v2 = <0x3c>;
				interconnects = <0x39 0x01 0x00 0x39 0x03 0x00 0x05 0x00 0x00 0x36 0x27 0x00>;
				interconnect-names = "qup-core", "qup-config";
				status = "disabled";
			};

			i2c@a84000 {
				compatible = "qcom,geni-i2c";
				reg = <0x00 0xa84000 0x00 0x4000>;
				clock-names = "se";
				clocks = <0x32 0x4a>;
				pinctrl-names = "default";
				pinctrl-0 = <0x59>;
				interrupts = <0x00 0x162 0x04>;
				#address-cells = <0x01>;
				#size-cells = <0x00>;
				interconnects = <0x39 0x01 0x00 0x39 0x03 0x00 0x05 0x00 0x00 0x36 0x27 0x00 0x55 0x02 0x00 0x06 0x01 0x00>;
				interconnect-names = "qup-core", "qup-config", "qup-memory";
				power-domains = <0x31 0x00>;
				required-opps = <0x21>;
				status = "okay";
				dmas = <0x5a 0x00 0x01 0x03 0x5a 0x01 0x01 0x03>;
				dma-names = "tx", "rx";
				clock-frequency = <0x61a80>;

				touchscreen@49 {
					compatible = "st,stmfts_fts5cu56a";
					reg = <0x49>;
					pinctrl-names = "default";
					pinctrl-0 = <0x5b>;
					interrupt-parent = <0x48>;
					interrupts = <0x09 0x2008>;
					vdd-supply = <0x4a>;
					avdd-supply = <0x5c>;
				};
			};

			serial@a84000 {
				compatible = "qcom,geni-uart";
				reg = <0x00 0xa84000 0x00 0x4000>;
				clock-names = "se";
				clocks = <0x32 0x4a>;
				pinctrl-names = "default";
				pinctrl-0 = <0x5d>;
				interrupts = <0x00 0x162 0x04>;
				power-domains = <0x31 0x00>;
				operating-points-v2 = <0x3c>;
				interconnects = <0x39 0x01 0x00 0x39 0x03 0x00 0x05 0x00 0x00 0x36 0x27 0x00>;
				interconnect-names = "qup-core", "qup-config";
				status = "disabled";
			};

			i2c@a88000 {
				compatible = "qcom,geni-i2c";
				reg = <0x00 0xa88000 0x00 0x4000>;
				clock-names = "se";
				clocks = <0x32 0x4c>;
				pinctrl-names = "default";
				pinctrl-0 = <0x5e>;
				interrupts = <0x00 0x163 0x04>;
				#address-cells = <0x01>;
				#size-cells = <0x00>;
				interconnects = <0x39 0x01 0x00 0x39 0x03 0x00 0x05 0x00 0x00 0x36 0x27 0x00 0x55 0x02 0x00 0x06 0x01 0x00>;
				interconnect-names = "qup-core", "qup-config", "qup-memory";
				power-domains = <0x31 0x00>;
				required-opps = <0x21>;
				status = "disabled";
			};

			spi@a88000 {
				compatible = "qcom,geni-spi";
				reg = <0x00 0xa88000 0x00 0x4000>;
				clock-names = "se";
				clocks = <0x32 0x4c>;
				pinctrl-names = "default";
				pinctrl-0 = <0x5f 0x60>;
				interrupts = <0x00 0x163 0x04>;
				#address-cells = <0x01>;
				#size-cells = <0x00>;
				power-domains = <0x31 0x00>;
				operating-points-v2 = <0x3c>;
				interconnects = <0x39 0x01 0x00 0x39 0x03 0x00 0x05 0x00 0x00 0x36 0x27 0x00>;
				interconnect-names = "qup-core", "qup-config";
				status = "disabled";
			};

			serial@a88000 {
				compatible = "qcom,geni-debug-uart";
				reg = <0x00 0xa88000 0x00 0x4000>;
				clock-names = "se";
				clocks = <0x32 0x4c>;
				pinctrl-names = "default";
				pinctrl-0 = <0x61>;
				interrupts = <0x00 0x163 0x04>;
				power-domains = <0x31 0x00>;
				operating-points-v2 = <0x3c>;
				interconnects = <0x39 0x01 0x00 0x39 0x03 0x00 0x05 0x00 0x00 0x36 0x27 0x00>;
				interconnect-names = "qup-core", "qup-config";
				status = "disabled";
			};

			i2c@a8c000 {
				compatible = "qcom,geni-i2c";
				reg = <0x00 0xa8c000 0x00 0x4000>;
				clock-names = "se";
				clocks = <0x32 0x4e>;
				pinctrl-names = "default";
				pinctrl-0 = <0x62>;
				interrupts = <0x00 0x164 0x04>;
				#address-cells = <0x01>;
				#size-cells = <0x00>;
				interconnects = <0x39 0x01 0x00 0x39 0x03 0x00 0x05 0x00 0x00 0x36 0x27 0x00 0x55 0x02 0x00 0x06 0x01 0x00>;
				interconnect-names = "qup-core", "qup-config", "qup-memory";
				power-domains = <0x31 0x00>;
				required-opps = <0x21>;
				status = "disabled";
			};

			serial@a8c000 {
				compatible = "qcom,geni-uart";
				reg = <0x00 0xa8c000 0x00 0x4000>;
				clock-names = "se";
				clocks = <0x32 0x4e>;
				pinctrl-names = "default";
				pinctrl-0 = <0x63>;
				interrupts = <0x00 0x164 0x04>;
				power-domains = <0x31 0x00>;
				operating-points-v2 = <0x3c>;
				interconnects = <0x39 0x01 0x00 0x39 0x03 0x00 0x05 0x00 0x00 0x36 0x27 0x00>;
				interconnect-names = "qup-core", "qup-config";
				status = "disabled";
			};

			i2c@a90000 {
				compatible = "qcom,geni-i2c";
				reg = <0x00 0xa90000 0x00 0x4000>;
				clock-names = "se";
				clocks = <0x32 0x50>;
				pinctrl-names = "default";
				pinctrl-0 = <0x64>;
				interrupts = <0x00 0x165 0x04>;
				#address-cells = <0x01>;
				#size-cells = <0x00>;
				interconnects = <0x39 0x01 0x00 0x39 0x03 0x00 0x05 0x00 0x00 0x36 0x27 0x00 0x55 0x02 0x00 0x06 0x01 0x00>;
				interconnect-names = "qup-core", "qup-config", "qup-memory";
				power-domains = <0x31 0x00>;
				required-opps = <0x21>;
				status = "disabled";
			};

			spi@a90000 {
				compatible = "qcom,geni-spi";
				reg = <0x00 0xa90000 0x00 0x4000>;
				clock-names = "se";
				clocks = <0x32 0x50>;
				pinctrl-names = "default";
				pinctrl-0 = <0x65 0x66>;
				interrupts = <0x00 0x165 0x04>;
				#address-cells = <0x01>;
				#size-cells = <0x00>;
				power-domains = <0x31 0x00>;
				operating-points-v2 = <0x3c>;
				interconnects = <0x39 0x01 0x00 0x39 0x03 0x00 0x05 0x00 0x00 0x36 0x27 0x00>;
				interconnect-names = "qup-core", "qup-config";
				status = "disabled";
			};

			serial@a90000 {
				compatible = "qcom,geni-uart";
				reg = <0x00 0xa90000 0x00 0x4000>;
				clock-names = "se";
				clocks = <0x32 0x50>;
				pinctrl-names = "default";
				pinctrl-0 = <0x67>;
				interrupts = <0x00 0x165 0x04>;
				power-domains = <0x31 0x00>;
				operating-points-v2 = <0x3c>;
				interconnects = <0x39 0x01 0x00 0x39 0x03 0x00 0x05 0x00 0x00 0x36 0x27 0x00>;
				interconnect-names = "qup-core", "qup-config";
				status = "disabled";
			};

			i2c@a94000 {
				compatible = "qcom,geni-i2c";
				reg = <0x00 0xa94000 0x00 0x4000>;
				clock-names = "se";
				clocks = <0x32 0x52>;
				pinctrl-names = "default";
				pinctrl-0 = <0x68>;
				interrupts = <0x00 0x166 0x04>;
				#address-cells = <0x01>;
				#size-cells = <0x00>;
				interconnects = <0x39 0x01 0x00 0x39 0x03 0x00 0x05 0x00 0x00 0x36 0x27 0x00 0x55 0x02 0x00 0x06 0x01 0x00>;
				interconnect-names = "qup-core", "qup-config", "qup-memory";
				power-domains = <0x31 0x00>;
				required-opps = <0x21>;
				status = "disabled";
			};

			spi@a94000 {
				compatible = "qcom,geni-spi";
				reg = <0x00 0xa94000 0x00 0x4000>;
				clock-names = "se";
				clocks = <0x32 0x52>;
				pinctrl-names = "default";
				pinctrl-0 = <0x69 0x6a>;
				interrupts = <0x00 0x166 0x04>;
				#address-cells = <0x01>;
				#size-cells = <0x00>;
				power-domains = <0x31 0x00>;
				operating-points-v2 = <0x3c>;
				interconnects = <0x39 0x01 0x00 0x39 0x03 0x00 0x05 0x00 0x00 0x36 0x27 0x00>;
				interconnect-names = "qup-core", "qup-config";
				status = "disabled";
			};

			serial@a94000 {
				compatible = "qcom,geni-uart";
				reg = <0x00 0xa94000 0x00 0x4000>;
				clock-names = "se";
				clocks = <0x32 0x52>;
				pinctrl-names = "default";
				pinctrl-0 = <0x6b>;
				interrupts = <0x00 0x166 0x04>;
				power-domains = <0x31 0x00>;
				operating-points-v2 = <0x3c>;
				interconnects = <0x39 0x01 0x00 0x39 0x03 0x00 0x05 0x00 0x00 0x36 0x27 0x00>;
				interconnect-names = "qup-core", "qup-config";
				status = "disabled";
			};
		};

		interconnect@1500000 {
			compatible = "qcom,sc7180-config-noc";
			reg = <0x00 0x1500000 0x00 0x28000>;
			#interconnect-cells = <0x02>;
			qcom,bcm-voters = <0x6c>;
			phandle = <0x36>;
		};

		interconnect@1620000 {
			compatible = "qcom,sc7180-system-noc";
			reg = <0x00 0x1620000 0x00 0x17080>;
			#interconnect-cells = <0x02>;
			qcom,bcm-voters = <0x6c>;
			phandle = <0x75>;
		};

		interconnect@1638000 {
			compatible = "qcom,sc7180-mc-virt";
			reg = <0x00 0x1638000 0x00 0x1000>;
			#interconnect-cells = <0x02>;
			qcom,bcm-voters = <0x6c>;
			phandle = <0x06>;
		};

		interconnect@1650000 {
			compatible = "qcom,sc7180-qup-virt";
			reg = <0x00 0x1650000 0x00 0x1000>;
			#interconnect-cells = <0x02>;
			qcom,bcm-voters = <0x6c>;
			phandle = <0x39>;
		};

		interconnect@16e0000 {
			compatible = "qcom,sc7180-aggre1-noc";
			reg = <0x00 0x16e0000 0x00 0x15080>;
			#interconnect-cells = <0x02>;
			qcom,bcm-voters = <0x6c>;
			phandle = <0x35>;
		};

		interconnect@1705000 {
			compatible = "qcom,sc7180-aggre2-noc";
			reg = <0x00 0x1705000 0x00 0x9000>;
			#interconnect-cells = <0x02>;
			qcom,bcm-voters = <0x6c>;
			phandle = <0x55>;
		};

		interconnect@170e000 {
			compatible = "qcom,sc7180-compute-noc";
			reg = <0x00 0x170e000 0x00 0x6000>;
			#interconnect-cells = <0x02>;
			qcom,bcm-voters = <0x6c>;
		};

		interconnect@1740000 {
			compatible = "qcom,sc7180-mmss-noc";
			reg = <0x00 0x1740000 0x00 0x1c100>;
			#interconnect-cells = <0x02>;
			qcom,bcm-voters = <0x6c>;
			phandle = <0xb7>;
		};

		ufshc@1d84000 {
			compatible = "qcom,sc7180-ufshc", "qcom,ufshc", "jedec,ufs-2.0";
			reg = <0x00 0x1d84000 0x00 0x3000>;
			interrupts = <0x00 0x109 0x04>;
			phys = <0x6d>;
			phy-names = "ufsphy";
			lanes-per-direction = <0x01>;
			#reset-cells = <0x01>;
			resets = <0x32 0x02>;
			reset-names = "rst";
			power-domains = <0x32 0x00>;
			iommus = <0x34 0xa0 0x00>;
			clock-names = "core_clk", "bus_aggr_clk", "iface_clk", "core_clk_unipro", "ref_clk", "tx_lane0_sync_clk", "rx_lane0_sync_clk";
			clocks = <0x32 0x63 0x32 0x07 0x32 0x62 0x32 0x6b 0x2f 0x00 0x32 0x6a 0x32 0x69>;
			freq-table-hz = <0x2faf080 0xbebc200 0x00 0x00 0x00 0x00 0x23c3460 0x8f0d180 0x00 0x00 0x00 0x00 0x00 0x00>;
			interconnects = <0x35 0x05 0x07 0x06 0x01 0x07 0x05 0x00 0x07 0x36 0x2f 0x07>;
			interconnect-names = "ufs-ddr", "cpu-ufs";
			qcom,ice = <0x6e>;
			status = "okay";
			vcc-supply = <0x6f>;
			vcc-max-microamp = <0x927c0>;
			vccq2-supply = <0x70>;
			vccq2-max-microamp = <0x927c0>;
			phandle = <0x71>;
		};

		phy@1d87000 {
			compatible = "qcom,sc7180-qmp-ufs-phy", "qcom,sm7150-qmp-ufs-phy";
			reg = <0x00 0x1d87000 0x00 0x1000>;
			clocks = <0x2f 0x00 0x32 0x67 0x32 0x61>;
			clock-names = "ref", "ref_aux", "qref";
			power-domains = <0x32 0x00>;
			resets = <0x71 0x00>;
			reset-names = "ufsphy";
			#phy-cells = <0x00>;
			status = "okay";
			vdda-phy-supply = <0x72>;
			vdda-pll-supply = <0x73>;
			phandle = <0x6d>;
		};

		crypto@1d90000 {
			compatible = "qcom,sc7180-inline-crypto-engine", "qcom,inline-crypto-engine";
			reg = <0x00 0x1d90000 0x00 0x8000>;
			clocks = <0x32 0x65>;
			phandle = <0x6e>;
		};

		ipa@1e40000 {
			compatible = "qcom,sc7180-ipa";
			iommus = <0x34 0x440 0x00 0x34 0x442 0x00>;
			reg = <0x00 0x1e40000 0x00 0x7000 0x00 0x1e47000 0x00 0x2000 0x00 0x1e04000 0x00 0x2c000>;
			reg-names = "ipa-reg", "ipa-shared", "gsi";
			interrupts-extended = <0x01 0x00 0x137 0x01 0x01 0x00 0x1b0 0x04 0x74 0x00 0x01 0x74 0x01 0x01>;
			interrupt-names = "ipa", "gsi", "ipa-clock-query", "ipa-setup-ready";
			clocks = <0x2f 0x0c>;
			clock-names = "core";
			interconnects = <0x55 0x05 0x00 0x06 0x01 0x00 0x55 0x05 0x00 0x75 0x09 0x00 0x05 0x00 0x00 0x36 0x19 0x00>;
			interconnect-names = "memory", "imem", "config";
			qcom,qmp = <0x76>;
			qcom,smem-states = <0x77 0x00 0x77 0x01>;
			qcom,smem-state-names = "ipa-clock-enabled-valid", "ipa-clock-enabled";
			status = "okay";
			memory-region = <0x78>;
			firmware-name = "qcom/sm7125/a52q/ipa_fws.mbn";
		};

		hwlock@1f40000 {
			compatible = "qcom,tcsr-mutex";
			reg = <0x00 0x1f40000 0x00 0x20000>;
			#hwlock-cells = <0x01>;
			phandle = <0x2d>;
		};

		syscon@1f60000 {
			compatible = "qcom,sc7180-tcsr", "syscon";
			reg = <0x00 0x1f60000 0x00 0x20000>;
		};

		syscon@1fc0000 {
			compatible = "qcom,sc7180-tcsr", "syscon";
			reg = <0x00 0x1fc0000 0x00 0x40000>;
		};

		pinctrl@3500000 {
			compatible = "qcom,sc7180-pinctrl";
			reg = <0x00 0x3500000 0x00 0x300000 0x00 0x3900000 0x00 0x300000 0x00 0x3d00000 0x00 0x300000>;
			reg-names = "west", "north", "south";
			interrupts = <0x00 0xd0 0x04>;
			gpio-controller;
			#gpio-cells = <0x02>;
			interrupt-controller;
			#interrupt-cells = <0x02>;
			gpio-ranges = <0x48 0x00 0x00 0x78>;
			wakeup-parent = <0x79>;
			gpio-reserved-ranges = <0x3b 0x04>;
			phandle = <0x48>;

			dp-hot-plug-det-state {
				pins = "gpio117";
				function = "dp_hot";
			};

			qspi-clk-state {
				pins = "gpio63";
				function = "qspi_clk";
			};

			qspi-cs0-state {
				pins = "gpio68";
				function = "qspi_cs";
			};

			qspi-cs1-state {
				pins = "gpio72";
				function = "qspi_cs";
			};

			qspi-data0-state {
				pins = "gpio64";
				function = "qspi_data";
			};

			qspi-data1-state {
				pins = "gpio65";
				function = "qspi_data";
			};

			qspi-data23-state {
				pins = "gpio66", "gpio67";
				function = "qspi_data";
			};

			qup-i2c0-default-state {
				pins = "gpio34", "gpio35";
				function = "qup00";
				phandle = <0x38>;
			};

			qup-i2c1-default-state {
				pins = "gpio0", "gpio1";
				function = "qup01";
				phandle = <0x3e>;
			};

			qup-i2c2-default-state {
				pins = "gpio15", "gpio16";
				function = "qup02_i2c";
				phandle = <0x42>;
			};

			qup-i2c3-default-state {
				pins = "gpio38", "gpio39";
				function = "qup03";
				phandle = <0x44>;
			};

			qup-i2c4-default-state {
				pins = "gpio115", "gpio116";
				function = "qup04_i2c";
				drive-strength = <0x02>;
				bias-disable;
				phandle = <0x4e>;
			};

			qup-i2c5-default-state {
				pins = "gpio25", "gpio26";
				function = "qup05";
				phandle = <0x50>;
			};

			qup-i2c6-default-state {
				pins = "gpio59", "gpio60";
				function = "qup10";
				phandle = <0x54>;
			};

			qup-i2c7-default-state {
				pins = "gpio6", "gpio7";
				function = "qup11_i2c";
				drive-strength = <0x02>;
				bias-disable;
				phandle = <0x59>;
			};

			qup-i2c8-default-state {
				pins = "gpio42", "gpio43";
				function = "qup12";
				phandle = <0x5e>;
			};

			qup-i2c9-default-state {
				pins = "gpio46", "gpio47";
				function = "qup13_i2c";
				phandle = <0x62>;
			};

			qup-i2c10-default-state {
				pins = "gpio86", "gpio87";
				function = "qup14";
				phandle = <0x64>;
			};

			qup-i2c11-default-state {
				pins = "gpio53", "gpio54";
				function = "qup15";
				phandle = <0x68>;
			};

			qup-spi0-spi-state {
				pins = "gpio34", "gpio35", "gpio36";
				function = "qup00";
				phandle = <0x3a>;
			};

			qup-spi0-cs-state {
				pins = "gpio37";
				function = "qup00";
				phandle = <0x3b>;
			};

			qup-spi0-cs-gpio-state {
				pins = "gpio37";
				function = "gpio";
			};

			qup-spi1-spi-state {
				pins = "gpio0", "gpio1", "gpio2";
				function = "qup01";
				phandle = <0x3f>;
			};

			qup-spi1-cs-state {
				pins = "gpio3";
				function = "qup01";
				phandle = <0x40>;
			};

			qup-spi1-cs-gpio-state {
				pins = "gpio3";
				function = "gpio";
			};

			qup-spi3-spi-state {
				pins = "gpio38", "gpio39", "gpio40";
				function = "qup03";
				phandle = <0x45>;
			};

			qup-spi3-cs-state {
				pins = "gpio41";
				function = "qup03";
				phandle = <0x46>;
			};

			qup-spi3-cs-gpio-state {
				pins = "gpio41";
				function = "gpio";
			};

			qup-spi5-spi-state {
				pins = "gpio25", "gpio26", "gpio27";
				function = "qup05";
				phandle = <0x51>;
			};

			qup-spi5-cs-state {
				pins = "gpio28";
				function = "qup05";
				phandle = <0x52>;
			};

			qup-spi5-cs-gpio-state {
				pins = "gpio28";
				function = "gpio";
			};

			qup-spi6-spi-state {
				pins = "gpio59", "gpio60", "gpio61";
				function = "qup10";
				phandle = <0x56>;
			};

			qup-spi6-cs-state {
				pins = "gpio62";
				function = "qup10";
				phandle = <0x57>;
			};

			qup-spi6-cs-gpio-state {
				pins = "gpio62";
				function = "gpio";
			};

			qup-spi8-spi-state {
				pins = "gpio42", "gpio43", "gpio44";
				function = "qup12";
				phandle = <0x5f>;
			};

			qup-spi8-cs-state {
				pins = "gpio45";
				function = "qup12";
				phandle = <0x60>;
			};

			qup-spi8-cs-gpio-state {
				pins = "gpio45";
				function = "gpio";
			};

			qup-spi10-spi-state {
				pins = "gpio86", "gpio87", "gpio88";
				function = "qup14";
				phandle = <0x65>;
			};

			qup-spi10-cs-state {
				pins = "gpio89";
				function = "qup14";
				phandle = <0x66>;
			};

			qup-spi10-cs-gpio-state {
				pins = "gpio89";
				function = "gpio";
			};

			qup-spi11-spi-state {
				pins = "gpio53", "gpio54", "gpio55";
				function = "qup15";
				phandle = <0x69>;
			};

			qup-spi11-cs-state {
				pins = "gpio56";
				function = "qup15";
				phandle = <0x6a>;
			};

			qup-spi11-cs-gpio-state {
				pins = "gpio56";
				function = "gpio";
			};

			qup-uart0-default-state {
				phandle = <0x3d>;

				cts-pins {
					pins = "gpio34";
					function = "qup00";
				};

				rts-pins {
					pins = "gpio35";
					function = "qup00";
				};

				tx-pins {
					pins = "gpio36";
					function = "qup00";
				};

				rx-pins {
					pins = "gpio37";
					function = "qup00";
				};
			};

			qup-uart1-default-state {
				phandle = <0x41>;

				cts-pins {
					pins = "gpio0";
					function = "qup01";
				};

				rts-pins {
					pins = "gpio1";
					function = "qup01";
				};

				tx-pins {
					pins = "gpio2";
					function = "qup01";
				};

				rx-pins {
					pins = "gpio3";
					function = "qup01";
				};
			};

			qup-uart2-default-state {
				phandle = <0x43>;

				tx-pins {
					pins = "gpio15";
					function = "qup02_uart";
				};

				rx-pins {
					pins = "gpio16";
					function = "qup02_uart";
				};
			};

			qup-uart3-default-state {
				phandle = <0x47>;

				cts-pins {
					pins = "gpio38";
					function = "qup03";
				};

				rts-pins {
					pins = "gpio39";
					function = "qup03";
				};

				tx-pins {
					pins = "gpio40";
					function = "qup03";
				};

				rx-pins {
					pins = "gpio41";
					function = "qup03";
				};
			};

			qup-uart4-default-state {
				phandle = <0x4f>;

				tx-pins {
					pins = "gpio115";
					function = "qup04_uart";
				};

				rx-pins {
					pins = "gpio116";
					function = "qup04_uart";
				};
			};

			qup-uart5-default-state {
				phandle = <0x53>;

				cts-pins {
					pins = "gpio25";
					function = "qup05";
				};

				rts-pins {
					pins = "gpio26";
					function = "qup05";
				};

				tx-pins {
					pins = "gpio27";
					function = "qup05";
				};

				rx-pins {
					pins = "gpio28";
					function = "qup05";
				};
			};

			qup-uart6-default-state {
				phandle = <0x58>;

				cts-pins {
					pins = "gpio59";
					function = "qup10";
				};

				rts-pins {
					pins = "gpio60";
					function = "qup10";
				};

				tx-pins {
					pins = "gpio61";
					function = "qup10";
				};

				rx-pins {
					pins = "gpio62";
					function = "qup10";
				};
			};

			qup-uart7-default-state {
				phandle = <0x5d>;

				tx-pins {
					pins = "gpio6";
					function = "qup11_uart";
				};

				rx-pins {
					pins = "gpio7";
					function = "qup11_uart";
				};
			};

			qup-uart8-default-state {
				phandle = <0x61>;

				tx-pins {
					pins = "gpio44";
					function = "qup12";
				};

				rx-pins {
					pins = "gpio45";
					function = "qup12";
				};
			};

			qup-uart9-default-state {
				phandle = <0x63>;

				tx-pins {
					pins = "gpio46";
					function = "qup13_uart";
				};

				rx-pins {
					pins = "gpio47";
					function = "qup13_uart";
				};
			};

			qup-uart10-default-state {
				phandle = <0x67>;

				cts-pins {
					pins = "gpio86";
					function = "qup14";
				};

				rts-pins {
					pins = "gpio87";
					function = "qup14";
				};

				tx-pins {
					pins = "gpio88";
					function = "qup14";
				};

				rx-pins {
					pins = "gpio89";
					function = "qup14";
				};
			};

			qup-uart11-default-state {
				phandle = <0x6b>;

				cts-pins {
					pins = "gpio53";
					function = "qup15";
				};

				rts-pins {
					pins = "gpio54";
					function = "qup15";
				};

				tx-pins {
					pins = "gpio55";
					function = "qup15";
				};

				rx-pins {
					pins = "gpio56";
					function = "qup15";
				};
			};

			sec-mi2s-active-state {
				pins = "gpio49", "gpio50", "gpio51";
				function = "mi2s_1";
			};

			pri-mi2s-active-state {
				pins = "gpio53", "gpio54", "gpio55", "gpio56";
				function = "mi2s_0";
			};

			pri-mi2s-mclk-active-state {
				pins = "gpio57";
				function = "lpass_ext";
			};

			ter-mi2s-active-state {
				pins = "gpio63", "gpio64", "gpio65", "gpio66";
				function = "mi2s_2";
			};

			cci0-default-state {
				pins = "gpio17", "gpio18";
				function = "cci_i2c";
				drive-strength = <0x02>;
				bias-pull-up;
				phandle = <0xbc>;
			};

			cci0-sleep-state {
				pins = "gpio17", "gpio18";
				function = "cci_i2c";
				drive-strength = <0x02>;
				bias-pull-down;
				phandle = <0xbe>;
			};

			cci1-default-state {
				pins = "gpio19", "gpio20";
				function = "cci_i2c";
				drive-strength = <0x02>;
				bias-pull-up;
				phandle = <0xbd>;
			};

			cci1-sleep-state {
				pins = "gpio19", "gpio20";
				function = "cci_i2c";
				drive-strength = <0x02>;
				bias-pull-down;
				phandle = <0xbf>;
			};

			cci2-default-state {
				pins = "gpio27", "gpio28";
				function = "cci_i2c";
				drive-strength = <0x02>;
				bias-pull-up;
				phandle = <0xc0>;
			};

			cci2-sleep-state {
				pins = "gpio27", "gpio28";
				function = "cci_i2c";
				drive-strength = <0x02>;
				bias-pull-down;
				phandle = <0xc1>;
			};

			mdss-dsi-active-state {
				pins = "gpio8";
				function = "gpio";
				drive-strength = <0x08>;
				bias-disable;
				phandle = <0xcb>;
			};

			mdss-dsi-suspend-state {
				pins = "gpio8";
				function = "gpio";
				drive-strength = <0x02>;
				bias-pull-down;
				phandle = <0xcd>;
			};

			mdss-te-active-state {
				pins = "gpio10";
				function = "mdp_vsync";
				drive-strength = <0x02>;
				bias-pull-down;
				phandle = <0xcc>;
			};

			mdss-te-suspend-state {
				pins = "gpio10";
				function = "mdp_vsync";
				drive-strength = <0x02>;
				bias-pull-down;
				phandle = <0xce>;
			};

			qup-uart3-sleep-state {
				phandle = <0x49>;

				pinmux {
					pins = "gpio38", "gpio39", "gpio40", "gpio41";
					function = "gpio";
				};

				pinconf-cts {
					pins = "gpio38";
					bias-pull-down;
				};

				pinconf-rts {
					pins = "gpio39";
					bias-pull-down;
				};

				pinconf-tx {
					pins = "gpio40";
					bias-pull-up;
				};

				pinconf-rx {
					pins = "gpio41";
					bias-pull-up;
				};
			};

			tsp-int-state {
				pins = "gpio9";
				function = "gpio";
				input-enable;
				bias-disable;
				phandle = <0x5b>;
			};

			sdc2-on-state {
				phandle = <0xa9>;

				pinconf-clk {
					pins = "sdc2_clk";
					bias-disable;
					drive-strength = <0x10>;
				};

				pinconf-cmd {
					pins = "sdc2_cmd";
					bias-pull-up;
					drive-strength = <0x0a>;
				};

				pinconf-data {
					pins = "sdc2_data";
					bias-pull-up;
					drive-strength = <0x0a>;
				};

				pinconf-sd-cd {
					pins = "gpio69";
					bias-pull-up;
					drive-strength = <0x02>;
				};
			};

			sdc2-off-state {
				phandle = <0xaa>;

				pinconf-clk {
					pins = "sdc2_clk";
					bias-disable;
					drive-strength = <0x02>;
				};

				pinconf-cmd {
					pins = "sdc2_cmd";
					bias-pull-up;
					drive-strength = <0x02>;
				};

				pinconf-data {
					pins = "sdc2_data";
					bias-pull-up;
					drive-strength = <0x02>;
				};

				pinconf-sd-cd {
					pins = "gpio69";
					bias-pull-up;
					drive-strength = <0x02>;
				};
			};

			tas2562-active-state {
				pins = "gpio88", "gpio89", "gpio90", "gpio94";
				function = "gpio";
				bias-disable;
				phandle = <0xf8>;
			};

			wcd-reset-n-active-state {
				pins = "gpio58";
				function = "gpio";
				drive-strength = <0x10>;
				bias-disable;
				output-low;
				phandle = <0x116>;
			};
		};

		remoteproc@4080000 {
			compatible = "qcom,sc7180-mpss-pas";
			reg = <0x00 0x4080000 0x00 0x4040>;
			interrupts-extended = <0x01 0x00 0x10a 0x01 0x7a 0x00 0x01 0x7a 0x01 0x01 0x7a 0x02 0x01 0x7a 0x03 0x01 0x7a 0x07 0x01>;
			interrupt-names = "wdog", "fatal", "ready", "handover", "stop-ack", "shutdown-ack";
			clocks = <0x2f 0x00>;
			clock-names = "xo";
			power-domains = <0x31 0x00 0x31 0x03 0x31 0x07>;
			power-domain-names = "cx", "mx", "mss";
			memory-region = <0x7b>;
			qcom,qmp = <0x76>;
			qcom,smem-states = <0x7c 0x00>;
			qcom,smem-state-names = "stop";
			status = "okay";
			firmware-name = "qcom/sm7125/a52q/modem.mbn";

			glink-edge {
				interrupts = <0x00 0x1c1 0x01>;
				label = "modem";
				qcom,remote-pid = <0x01>;
				mboxes = <0x2e 0x0c>;
			};
		};

		gpu@5000000 {
			compatible = "qcom,adreno-618.0", "qcom,adreno";
			reg = <0x00 0x5000000 0x00 0x40000 0x00 0x509e000 0x00 0x1000 0x00 0x5061000 0x00 0x800>;
			reg-names = "kgsl_3d0_reg_memory", "cx_mem", "cx_dbgc";
			interrupts = <0x00 0x12c 0x04>;
			iommus = <0x7d 0x00>;
			operating-points-v2 = <0x7e>;
			qcom,gmu = <0x7f>;
			#cooling-cells = <0x02>;
			nvmem-cells = <0x80>;
			nvmem-cell-names = "speed_bin";
			interconnects = <0x05 0x08 0x00 0x06 0x01 0x00>;
			interconnect-names = "gfx-mem";
			status = "okay";
			phandle = <0x10f>;

			opp-table {
				compatible = "operating-points-v2";
				phandle = <0x7e>;

				opp-650000000 {
					opp-hz = <0x00 0x26be3680>;
					opp-level = <0x140>;
					opp-peak-kBps = <0x6e1b80>;
					opp-supported-hw = <0x08>;
				};

				opp-565000000 {
					opp-hz = <0x00 0x21ad3740>;
					opp-level = <0x100>;
					opp-peak-kBps = <0x5294a0>;
					opp-supported-hw = <0x08>;
				};

				opp-430000000 {
					opp-hz = <0x00 0x19a14780>;
					opp-level = <0xc0>;
					opp-peak-kBps = <0x5294a0>;
					opp-supported-hw = <0x08>;
				};

				opp-355000000 {
					opp-hz = <0x00 0x1528dec0>;
					opp-level = <0x80>;
					opp-peak-kBps = <0x2ee000>;
					opp-supported-hw = <0x08>;
				};

				opp-267000000 {
					opp-hz = <0x00 0xfea18c0>;
					opp-level = <0x40>;
					opp-peak-kBps = <0x2ee000>;
					opp-supported-hw = <0x08>;
				};

				opp-180000000 {
					opp-hz = <0x00 0xaba9500>;
					opp-level = <0x30>;
					opp-peak-kBps = <0x1b86e0>;
					opp-supported-hw = <0x08>;
				};

				opp-750000000 {
					opp-hz = <0x00 0x2cb41780>;
					opp-level = <0x140>;
					opp-peak-kBps = <0x6e1b80>;
					opp-supported-hw = <0x08>;
				};
			};

			zap-shader {
				memory-region = <0x81>;
				firmware-name = "qcom/sm7125/a52q/a615_zap.mbn";
			};
		};

		iommu@5040000 {
			compatible = "qcom,sc7180-smmu-v2", "qcom,adreno-smmu", "qcom,smmu-v2";
			reg = <0x00 0x5040000 0x00 0x10000>;
			#iommu-cells = <0x01>;
			#global-interrupts = <0x02>;
			interrupts = <0x00 0xe5 0x04 0x00 0xe7 0x04 0x00 0x16c 0x01 0x00 0x16d 0x01 0x00 0x16e 0x01 0x00 0x16f 0x01 0x00 0x170 0x01 0x00 0x171 0x01 0x00 0x172 0x01 0x00 0x173 0x01>;
			clocks = <0x32 0x26 0x32 0x23>;
			clock-names = "bus", "iface";
			power-domains = <0x82 0x00>;
			phandle = <0x7d>;
		};

		gmu@506a000 {
			compatible = "qcom,adreno-gmu-618.0", "qcom,adreno-gmu";
			reg = <0x00 0x506a000 0x00 0x31000 0x00 0xb290000 0x00 0x10000 0x00 0xb490000 0x00 0x10000>;
			reg-names = "gmu", "gmu_pdc", "gmu_pdc_seq";
			interrupts = <0x00 0x130 0x04 0x00 0x131 0x04>;
			interrupt-names = "hfi", "gmu";
			clocks = <0x82 0x03 0x82 0x06 0x32 0x16 0x32 0x26>;
			clock-names = "gmu", "cxo", "axi", "memnoc";
			power-domains = <0x82 0x00 0x82 0x01>;
			power-domain-names = "cx", "gx";
			iommus = <0x7d 0x05>;
			operating-points-v2 = <0x83>;
			phandle = <0x7f>;

			opp-table {
				compatible = "operating-points-v2";
				phandle = <0x83>;

				opp-200000000 {
					opp-hz = <0x00 0xbebc200>;
					opp-level = <0x30>;
				};
			};
		};

		clock-controller@5090000 {
			compatible = "qcom,sc7180-gpucc";
			reg = <0x00 0x5090000 0x00 0x9000>;
			clocks = <0x2f 0x00 0x32 0x24 0x32 0x25>;
			clock-names = "bi_tcxo", "gcc_gpu_gpll0_clk_src", "gcc_gpu_gpll0_div_clk_src";
			#clock-cells = <0x01>;
			#reset-cells = <0x01>;
			#power-domain-cells = <0x01>;
			phandle = <0x82>;
		};

		dma@10a2000 {
			compatible = "qcom,sc7180-dcc", "qcom,dcc";
			reg = <0x00 0x10a2000 0x00 0x1000 0x00 0x10ae000 0x00 0x2000>;
			status = "disabled";
		};

		stm@6002000 {
			compatible = "arm,coresight-stm", "arm,primecell";
			reg = <0x00 0x6002000 0x00 0x1000 0x00 0x16280000 0x00 0x180000>;
			reg-names = "stm-base", "stm-stimulus-base";
			clocks = <0x76>;
			clock-names = "apb_pclk";

			out-ports {

				port {

					endpoint {
						remote-endpoint = <0x84>;
						phandle = <0x86>;
					};
				};
			};
		};

		funnel@6041000 {
			compatible = "arm,coresight-dynamic-funnel", "arm,primecell";
			reg = <0x00 0x6041000 0x00 0x1000>;
			clocks = <0x76>;
			clock-names = "apb_pclk";

			out-ports {

				port {

					endpoint {
						remote-endpoint = <0x85>;
						phandle = <0x8a>;
					};
				};
			};

			in-ports {
				#address-cells = <0x01>;
				#size-cells = <0x00>;

				port@7 {
					reg = <0x07>;

					endpoint {
						remote-endpoint = <0x86>;
						phandle = <0x84>;
					};
				};
			};
		};

		funnel@6042000 {
			compatible = "arm,coresight-dynamic-funnel", "arm,primecell";
			reg = <0x00 0x6042000 0x00 0x1000>;
			clocks = <0x76>;
			clock-names = "apb_pclk";

			out-ports {

				port {

					endpoint {
						remote-endpoint = <0x87>;
						phandle = <0x8b>;
					};
				};
			};

			in-ports {
				#address-cells = <0x01>;
				#size-cells = <0x00>;

				port@4 {
					reg = <0x04>;

					endpoint {
						remote-endpoint = <0x88>;
						phandle = <0xa6>;
					};
				};
			};
		};

		funnel@6045000 {
			compatible = "arm,coresight-dynamic-funnel", "arm,primecell";
			reg = <0x00 0x6045000 0x00 0x1000>;
			clocks = <0x76>;
			clock-names = "apb_pclk";

			out-ports {

				port {

					endpoint {
						remote-endpoint = <0x89>;
						phandle = <0x90>;
					};
				};
			};

			in-ports {
				#address-cells = <0x01>;
				#size-cells = <0x00>;

				port@0 {
					reg = <0x00>;

					endpoint {
						remote-endpoint = <0x8a>;
						phandle = <0x85>;
					};
				};

				port@1 {
					reg = <0x01>;

					endpoint {
						remote-endpoint = <0x8b>;
						phandle = <0x87>;
					};
				};
			};
		};

		replicator@6046000 {
			compatible = "arm,coresight-dynamic-replicator", "arm,primecell";
			reg = <0x00 0x6046000 0x00 0x1000>;
			clocks = <0x76>;
			clock-names = "apb_pclk";

			out-ports {

				port {

					endpoint {
						remote-endpoint = <0x8c>;
						phandle = <0x8e>;
					};
				};
			};

			in-ports {

				port {

					endpoint {
						remote-endpoint = <0x8d>;
						phandle = <0x93>;
					};
				};
			};
		};

		etr@6048000 {
			compatible = "arm,coresight-tmc", "arm,primecell";
			reg = <0x00 0x6048000 0x00 0x1000>;
			iommus = <0x34 0x4a0 0x20>;
			clocks = <0x76>;
			clock-names = "apb_pclk";
			arm,scatter-gather;

			in-ports {

				port {

					endpoint {
						remote-endpoint = <0x8e>;
						phandle = <0x8c>;
					};
				};
			};
		};

		funnel@6b04000 {
			compatible = "arm,coresight-dynamic-funnel", "arm,primecell";
			reg = <0x00 0x6b04000 0x00 0x1000>;
			clocks = <0x76>;
			clock-names = "apb_pclk";

			out-ports {

				port {

					endpoint {
						remote-endpoint = <0x8f>;
						phandle = <0x92>;
					};
				};
			};

			in-ports {
				#address-cells = <0x01>;
				#size-cells = <0x00>;

				port@7 {
					reg = <0x07>;

					endpoint {
						remote-endpoint = <0x90>;
						phandle = <0x89>;
					};
				};
			};
		};

		etf@6b05000 {
			compatible = "arm,coresight-tmc", "arm,primecell";
			reg = <0x00 0x6b05000 0x00 0x1000>;
			clocks = <0x76>;
			clock-names = "apb_pclk";

			out-ports {

				port {

					endpoint {
						remote-endpoint = <0x91>;
						phandle = <0x94>;
					};
				};
			};

			in-ports {

				port {

					endpoint {
						remote-endpoint = <0x92>;
						phandle = <0x8f>;
					};
				};
			};
		};

		replicator@6b06000 {
			compatible = "arm,coresight-dynamic-replicator", "arm,primecell";
			reg = <0x00 0x6b06000 0x00 0x1000>;
			clocks = <0x76>;
			clock-names = "apb_pclk";
			qcom,replicator-loses-context;

			out-ports {

				port {

					endpoint {
						remote-endpoint = <0x93>;
						phandle = <0x8d>;
					};
				};
			};

			in-ports {

				port {

					endpoint {
						remote-endpoint = <0x94>;
						phandle = <0x91>;
					};
				};
			};
		};

		etm@7040000 {
			compatible = "arm,coresight-etm4x", "arm,primecell";
			reg = <0x00 0x7040000 0x00 0x1000>;
			cpu = <0x19>;
			clocks = <0x76>;
			clock-names = "apb_pclk";
			arm,coresight-loses-context-with-cpu;
			qcom,skip-power-up;

			out-ports {

				port {

					endpoint {
						remote-endpoint = <0x95>;
						phandle = <0x9e>;
					};
				};
			};
		};

		etm@7140000 {
			compatible = "arm,coresight-etm4x", "arm,primecell";
			reg = <0x00 0x7140000 0x00 0x1000>;
			cpu = <0x1a>;
			clocks = <0x76>;
			clock-names = "apb_pclk";
			arm,coresight-loses-context-with-cpu;
			qcom,skip-power-up;

			out-ports {

				port {

					endpoint {
						remote-endpoint = <0x96>;
						phandle = <0x9f>;
					};
				};
			};
		};

		etm@7240000 {
			compatible = "arm,coresight-etm4x", "arm,primecell";
			reg = <0x00 0x7240000 0x00 0x1000>;
			cpu = <0x1b>;
			clocks = <0x76>;
			clock-names = "apb_pclk";
			arm,coresight-loses-context-with-cpu;
			qcom,skip-power-up;

			out-ports {

				port {

					endpoint {
						remote-endpoint = <0x97>;
						phandle = <0xa0>;
					};
				};
			};
		};

		etm@7340000 {
			compatible = "arm,coresight-etm4x", "arm,primecell";
			reg = <0x00 0x7340000 0x00 0x1000>;
			cpu = <0x1c>;
			clocks = <0x76>;
			clock-names = "apb_pclk";
			arm,coresight-loses-context-with-cpu;
			qcom,skip-power-up;

			out-ports {

				port {

					endpoint {
						remote-endpoint = <0x98>;
						phandle = <0xa1>;
					};
				};
			};
		};

		etm@7440000 {
			compatible = "arm,coresight-etm4x", "arm,primecell";
			reg = <0x00 0x7440000 0x00 0x1000>;
			cpu = <0x1d>;
			clocks = <0x76>;
			clock-names = "apb_pclk";
			arm,coresight-loses-context-with-cpu;
			qcom,skip-power-up;

			out-ports {

				port {

					endpoint {
						remote-endpoint = <0x99>;
						phandle = <0xa2>;
					};
				};
			};
		};

		etm@7540000 {
			compatible = "arm,coresight-etm4x", "arm,primecell";
			reg = <0x00 0x7540000 0x00 0x1000>;
			cpu = <0x1e>;
			clocks = <0x76>;
			clock-names = "apb_pclk";
			arm,coresight-loses-context-with-cpu;
			qcom,skip-power-up;

			out-ports {

				port {

					endpoint {
						remote-endpoint = <0x9a>;
						phandle = <0xa3>;
					};
				};
			};
		};

		etm@7640000 {
			compatible = "arm,coresight-etm4x", "arm,primecell";
			reg = <0x00 0x7640000 0x00 0x1000>;
			cpu = <0x1f>;
			clocks = <0x76>;
			clock-names = "apb_pclk";
			arm,coresight-loses-context-with-cpu;
			qcom,skip-power-up;

			out-ports {

				port {

					endpoint {
						remote-endpoint = <0x9b>;
						phandle = <0xa4>;
					};
				};
			};
		};

		etm@7740000 {
			compatible = "arm,coresight-etm4x", "arm,primecell";
			reg = <0x00 0x7740000 0x00 0x1000>;
			cpu = <0x20>;
			clocks = <0x76>;
			clock-names = "apb_pclk";
			arm,coresight-loses-context-with-cpu;
			qcom,skip-power-up;

			out-ports {

				port {

					endpoint {
						remote-endpoint = <0x9c>;
						phandle = <0xa5>;
					};
				};
			};
		};

		funnel@7800000 {
			compatible = "arm,coresight-dynamic-funnel", "arm,primecell";
			reg = <0x00 0x7800000 0x00 0x1000>;
			clocks = <0x76>;
			clock-names = "apb_pclk";

			out-ports {

				port {

					endpoint {
						remote-endpoint = <0x9d>;
						phandle = <0xa7>;
					};
				};
			};

			in-ports {
				#address-cells = <0x01>;
				#size-cells = <0x00>;

				port@0 {
					reg = <0x00>;

					endpoint {
						remote-endpoint = <0x9e>;
						phandle = <0x95>;
					};
				};

				port@1 {
					reg = <0x01>;

					endpoint {
						remote-endpoint = <0x9f>;
						phandle = <0x96>;
					};
				};

				port@2 {
					reg = <0x02>;

					endpoint {
						remote-endpoint = <0xa0>;
						phandle = <0x97>;
					};
				};

				port@3 {
					reg = <0x03>;

					endpoint {
						remote-endpoint = <0xa1>;
						phandle = <0x98>;
					};
				};

				port@4 {
					reg = <0x04>;

					endpoint {
						remote-endpoint = <0xa2>;
						phandle = <0x99>;
					};
				};

				port@5 {
					reg = <0x05>;

					endpoint {
						remote-endpoint = <0xa3>;
						phandle = <0x9a>;
					};
				};

				port@6 {
					reg = <0x06>;

					endpoint {
						remote-endpoint = <0xa4>;
						phandle = <0x9b>;
					};
				};

				port@7 {
					reg = <0x07>;

					endpoint {
						remote-endpoint = <0xa5>;
						phandle = <0x9c>;
					};
				};
			};
		};

		funnel@7810000 {
			compatible = "arm,coresight-dynamic-funnel", "arm,primecell";
			reg = <0x00 0x7810000 0x00 0x1000>;
			clocks = <0x76>;
			clock-names = "apb_pclk";

			out-ports {

				port {

					endpoint {
						remote-endpoint = <0xa6>;
						phandle = <0x88>;
					};
				};
			};

			in-ports {

				port {

					endpoint {
						remote-endpoint = <0xa7>;
						phandle = <0x9d>;
					};
				};
			};
		};

		mmc@8804000 {
			compatible = "qcom,sc7180-sdhci", "qcom,sdhci-msm-v5";
			reg = <0x00 0x8804000 0x00 0x1000>;
			iommus = <0x34 0x80 0x00>;
			interrupts = <0x00 0xcc 0x04 0x00 0xde 0x04>;
			interrupt-names = "hc_irq", "pwr_irq";
			clocks = <0x32 0x5d 0x32 0x5e 0x2f 0x00>;
			clock-names = "iface", "core", "xo";
			interconnects = <0x35 0x03 0x00 0x06 0x01 0x00 0x05 0x00 0x00 0x36 0x28 0x00>;
			interconnect-names = "sdhc-ddr", "cpu-sdhc";
			power-domains = <0x31 0x00>;
			operating-points-v2 = <0xa8>;
			bus-width = <0x04>;
			status = "okay";
			pinctrl-names = "default", "sleep";
			pinctrl-0 = <0xa9>;
			pinctrl-1 = <0xaa>;
			vmmc-supply = <0xab>;
			vqmmc-supply = <0xac>;
			cd-gpios = <0x48 0x45 0x01>;

			opp-table {
				compatible = "operating-points-v2";
				phandle = <0xa8>;

				opp-100000000 {
					opp-hz = <0x00 0x5f5e100>;
					required-opps = <0x21>;
					opp-peak-kBps = <0x1b7740 0x927c0>;
					opp-avg-kBps = <0x186a0 0x00>;
				};

				opp-202000000 {
					opp-hz = <0x00 0xc0a4680>;
					required-opps = <0x23>;
					opp-peak-kBps = <0x5265c0 0x186a00>;
					opp-avg-kBps = <0x30d40 0x00>;
				};
			};
		};

		spi@88dc000 {
			compatible = "qcom,sc7180-qspi", "qcom,qspi-v1";
			reg = <0x00 0x88dc000 0x00 0x600>;
			iommus = <0x34 0x20 0x00>;
			#address-cells = <0x01>;
			#size-cells = <0x00>;
			interrupts = <0x00 0x77 0x04>;
			clocks = <0x32 0x35 0x32 0x36>;
			clock-names = "iface", "core";
			interconnects = <0x05 0x00 0x00 0x36 0x25 0x00>;
			interconnect-names = "qspi-config";
			power-domains = <0x31 0x00>;
			operating-points-v2 = <0xad>;
			status = "disabled";
		};

		phy@88e3000 {
			compatible = "qcom,sc7180-qusb2-phy", "qcom,qusb2-v2-phy";
			reg = <0x00 0x88e3000 0x00 0x400>;
			status = "okay";
			#phy-cells = <0x00>;
			clocks = <0x32 0x77 0x2f 0x00>;
			clock-names = "cfg_ahb", "ref";
			resets = <0x32 0x00>;
			nvmem-cells = <0xae>;
			vdd-supply = <0x72>;
			vdda-pll-supply = <0x33>;
			vdda-phy-dpdm-supply = <0xaf>;
			phandle = <0xb2>;
		};

		phy@88e8000 {
			compatible = "qcom,sc7180-qmp-usb3-dp-phy";
			reg = <0x00 0x88e8000 0x00 0x3000>;
			status = "okay";
			clocks = <0x32 0x73 0x32 0x72 0x32 0x75 0x32 0x76 0x32 0x77>;
			clock-names = "aux", "ref", "com_aux", "usb3_pipe", "cfg_ahb";
			resets = <0x32 0x06 0x32 0x04>;
			reset-names = "phy", "common";
			#clock-cells = <0x01>;
			#phy-cells = <0x01>;
			vdda-phy-supply = <0x72>;
			vdda-pll-supply = <0x73>;
			phandle = <0xb3>;
		};

		pmu@90b6300 {
			compatible = "qcom,sc7180-cpu-bwmon", "qcom,sdm845-bwmon";
			reg = <0x00 0x90b6300 0x00 0x600>;
			interrupts = <0x00 0x245 0x04>;
			interconnects = <0x05 0x00 0x03 0x05 0x0b 0x03>;
			operating-points-v2 = <0xb0>;

			opp-table {
				compatible = "operating-points-v2";
				phandle = <0xb0>;

				opp-0 {
					opp-peak-kBps = <0x22e980>;
				};

				opp-1 {
					opp-peak-kBps = <0x45d6e8>;
				};

				opp-2 {
					opp-peak-kBps = <0x6c7d70>;
				};

				opp-3 {
					opp-peak-kBps = <0x8bb1b8>;
				};

				opp-4 {
					opp-peak-kBps = <0xbba710>;
				};

				opp-5 {
					opp-peak-kBps = <0xd93960>;
				};
			};
		};

		pmu@90cd000 {
			compatible = "qcom,sc7180-llcc-bwmon", "qcom,sc7280-llcc-bwmon";
			reg = <0x00 0x90cd000 0x00 0x1000>;
			interrupts = <0x00 0xf1 0x04>;
			interconnects = <0x06 0x00 0x03 0x06 0x01 0x03>;
			operating-points-v2 = <0xb1>;

			opp-table {
				compatible = "operating-points-v2";
				phandle = <0xb1>;

				opp-0 {
					opp-peak-kBps = <0x1174c0>;
				};

				opp-1 {
					opp-peak-kBps = <0x1a3ec0>;
				};

				opp-2 {
					opp-peak-kBps = <0x1fd470>;
				};

				opp-3 {
					opp-peak-kBps = <0x2cb168>;
				};

				opp-4 {
					opp-peak-kBps = <0x3b3058>;
				};

				opp-5 {
					opp-peak-kBps = <0x5a7ff8>;
				};

				opp-6 {
					opp-peak-kBps = <0x68fee8>;
				};

				opp-7 {
					opp-peak-kBps = <0x7c2928>;
				};
			};
		};

		interconnect@9160000 {
			compatible = "qcom,sc7180-dc-noc";
			reg = <0x00 0x9160000 0x00 0x3200>;
			#interconnect-cells = <0x02>;
			qcom,bcm-voters = <0x6c>;
		};

		system-cache-controller@9200000 {
			compatible = "qcom,sc7180-llcc";
			reg = <0x00 0x9200000 0x00 0x50000 0x00 0x9600000 0x00 0x50000>;
			reg-names = "llcc0_base", "llcc_broadcast_base";
			interrupts = <0x00 0x246 0x04>;
		};

		interconnect@9680000 {
			compatible = "qcom,sc7180-gem-noc";
			reg = <0x00 0x9680000 0x00 0x3e200>;
			#interconnect-cells = <0x02>;
			qcom,bcm-voters = <0x6c>;
			phandle = <0x05>;
		};

		interconnect@9990000 {
			compatible = "qcom,sc7180-npu-noc";
			reg = <0x00 0x9990000 0x00 0x1600>;
			#interconnect-cells = <0x02>;
			qcom,bcm-voters = <0x6c>;
		};

		usb@a6f8800 {
			compatible = "qcom,sc7180-dwc3", "qcom,dwc3";
			reg = <0x00 0xa6f8800 0x00 0x400>;
			status = "okay";
			#address-cells = <0x02>;
			#size-cells = <0x02>;
			ranges;
			dma-ranges;
			clocks = <0x32 0x11 0x32 0x6d 0x32 0x08 0x32 0x71 0x32 0x6f>;
			clock-names = "cfg_noc", "core", "iface", "sleep", "mock_utmi";
			assigned-clocks = <0x32 0x6f 0x32 0x6d>;
			assigned-clock-rates = <0x124f800 0x8f0d180>;
			interrupts-extended = <0x01 0x00 0x82 0x04 0x01 0x00 0x83 0x04 0x79 0x09 0x03 0x79 0x08 0x03 0x79 0x06 0x04>;
			interrupt-names = "pwr_event", "hs_phy_irq", "dp_hs_phy_irq", "dm_hs_phy_irq", "ss_phy_irq";
			power-domains = <0x32 0x01>;
			required-opps = <0x23>;
			resets = <0x32 0x03>;
			interconnects = <0x55 0x03 0x00 0x06 0x01 0x00 0x05 0x00 0x00 0x36 0x30 0x00>;
			interconnect-names = "usb-ddr", "apps-usb";
			wakeup-source;
			qcom,select-utmi-as-pipe-clk;

			usb@a600000 {
				compatible = "snps,dwc3";
				reg = <0x00 0xa600000 0x00 0xe000>;
				interrupts = <0x00 0x85 0x04>;
				iommus = <0x34 0x540 0x00>;
				snps,dis_u2_susphy_quirk;
				snps,dis_enblslpm_quirk;
				phys = <0xb2 0xb3 0x00>;
				phy-names = "usb2-phy", "usb3-phy";
				maximum-speed = "high-speed";
				dr_mode = "peripheral";
			};
		};

		video-codec@aa00000 {
			compatible = "qcom,sc7180-venus";
			reg = <0x00 0xaa00000 0x00 0xff000>;
			interrupts = <0x00 0xae 0x04>;
			power-domains = <0xb4 0x00 0xb4 0x01 0x31 0x00>;
			power-domain-names = "venus", "vcodec0", "cx";
			operating-points-v2 = <0xb5>;
			clocks = <0xb4 0x06 0xb4 0x03 0xb4 0x05 0xb4 0x02 0xb4 0x01>;
			clock-names = "core", "iface", "bus", "vcodec0_core", "vcodec0_bus";
			iommus = <0x34 0xc00 0x60>;
			memory-region = <0xb6>;
			interconnects = <0xb7 0x06 0x00 0x06 0x01 0x00 0x05 0x00 0x00 0x36 0x31 0x00>;
			interconnect-names = "video-mem", "cpu-cfg";
			firmware-name = "qcom/sm7125/a52q/venus.mbn";

			video-decoder {
				compatible = "venus-decoder";
			};

			video-encoder {
				compatible = "venus-encoder";
			};

			opp-table {
				compatible = "operating-points-v2";
				phandle = <0xb5>;

				opp-150000000 {
					opp-hz = <0x00 0x8f0d180>;
					required-opps = <0x21>;
				};

				opp-270000000 {
					opp-hz = <0x00 0x1017df80>;
					required-opps = <0x22>;
				};

				opp-340000000 {
					opp-hz = <0x00 0x1443fd00>;
					required-opps = <0xb8>;
				};

				opp-434000000 {
					opp-hz = <0x00 0x19de5080>;
					required-opps = <0x23>;
				};

				opp-500000097 {
					opp-hz = <0x00 0x1dcd6561>;
					required-opps = <0xb9>;
				};
			};
		};

		clock-controller@ab00000 {
			compatible = "qcom,sc7180-videocc";
			reg = <0x00 0xab00000 0x00 0x10000>;
			clocks = <0x2f 0x00>;
			clock-names = "bi_tcxo";
			#clock-cells = <0x01>;
			#reset-cells = <0x01>;
			#power-domain-cells = <0x01>;
			phandle = <0xb4>;
		};

		interconnect@ac00000 {
			compatible = "qcom,sc7180-camnoc-virt";
			reg = <0x00 0xac00000 0x00 0x1000>;
			#interconnect-cells = <0x02>;
			qcom,bcm-voters = <0x6c>;
			phandle = <0xbb>;
		};

		camss@acb3000 {
			compatible = "qcom,sc7180-camss";
			reg = <0x00 0xacb3000 0x00 0x1000 0x00 0xacba000 0x00 0x1000 0x00 0xacc8000 0x00 0x1000 0x00 0xac65000 0x00 0x1000 0x00 0xac66000 0x00 0x1000 0x00 0xac67000 0x00 0x1000 0x00 0xac68000 0x00 0x1000 0x00 0xacaf000 0x00 0x4000 0x00 0xacb6000 0x00 0x4000 0x00 0xacc4000 0x00 0x4000>;
			reg-names = "csid0", "csid1", "csid2", "csiphy0", "csiphy1", "csiphy2", "csiphy3", "vfe0", "vfe1", "vfe_lite";
			clocks = <0xba 0x06 0xba 0x0c 0xba 0x25 0xba 0x2c 0xba 0x32 0xba 0x16 0xba 0x0e 0xba 0x17 0xba 0x10 0xba 0x18 0xba 0x12 0xba 0x19 0xba 0x14 0x32 0x0a 0x32 0x0b 0xba 0x4d 0xba 0x21 0xba 0x22 0xba 0x24 0xba 0x28 0xba 0x29 0xba 0x2b 0xba 0x2f 0xba 0x31>;
			clock-names = "camnoc_axi", "cpas_ahb", "csi0", "csi1", "csi2", "csiphy0", "csiphy0_timer", "csiphy1", "csiphy1_timer", "csiphy2", "csiphy2_timer", "csiphy3", "csiphy3_timer", "gcc_camera_ahb", "gcc_camera_axi", "soc_ahb", "vfe0_axi", "vfe0", "vfe0_cphy_rx", "vfe1_axi", "vfe1", "vfe1_cphy_rx", "vfe_lite", "vfe_lite_cphy_rx";
			interrupts = <0x00 0x1d0 0x04 0x00 0x1d2 0x04 0x00 0x1d9 0x04 0x00 0x1dd 0x04 0x00 0x1de 0x04 0x00 0x1df 0x04 0x00 0x1cd 0x04 0x00 0x1d1 0x04 0x00 0x1d3 0x04 0x00 0x1d8 0x04>;
			interrupt-names = "csid0", "csid1", "csid2", "csiphy0", "csiphy1", "csiphy2", "csiphy3", "vfe0", "vfe1", "vfe_lite";
			iommus = <0x34 0x820 0x00 0x34 0x840 0x00 0x34 0x860 0x00>;
			interconnects = <0x05 0x00 0x00 0x36 0x09 0x00 0xbb 0x00 0x00 0xbb 0x03 0x00 0xbb 0x01 0x00 0xbb 0x03 0x00 0xbb 0x02 0x00 0xbb 0x03 0x00>;
			interconnect-names = "cam_ahb", "cam_hf_0_camnoc", "cam_hf_1_camnoc", "cam_sf_camnoc";
			power-domains = <0xba 0x01 0xba 0x02 0xba 0x04>;
			power-domain-names = "ife0", "ife1", "top";
			status = "disabled";

			ports {
				#address-cells = <0x01>;
				#size-cells = <0x00>;

				port@0 {
					reg = <0x00>;
				};

				port@1 {
					reg = <0x01>;
				};

				port@2 {
					reg = <0x02>;
				};

				port@3 {
					reg = <0x03>;
				};
			};
		};

		cci@ac4a000 {
			compatible = "qcom,sc7180-cci", "qcom,msm8996-cci";
			reg = <0x00 0xac4a000 0x00 0x1000>;
			interrupts = <0x00 0x1d4 0x01>;
			power-domains = <0xba 0x04>;
			clocks = <0xba 0x06 0xba 0x4d 0xba 0x4c 0xba 0x0c 0xba 0x07 0xba 0x08>;
			clock-names = "camnoc_axi", "soc_ahb", "slow_ahb_src", "cpas_ahb", "cci", "cci_src";
			pinctrl-0 = <0xbc 0xbd>;
			pinctrl-1 = <0xbe 0xbf>;
			pinctrl-names = "default", "sleep";
			status = "disabled";
			#address-cells = <0x01>;
			#size-cells = <0x00>;

			i2c-bus@0 {
				reg = <0x00>;
				clock-frequency = <0xf4240>;
				#address-cells = <0x01>;
				#size-cells = <0x00>;
			};

			i2c-bus@1 {
				reg = <0x01>;
				clock-frequency = <0xf4240>;
				#address-cells = <0x01>;
				#size-cells = <0x00>;
			};
		};

		cci@ac4b000 {
			compatible = "qcom,sc7180-cci", "qcom,msm8996-cci";
			reg = <0x00 0xac4b000 0x00 0x1000>;
			interrupts = <0x00 0x1ce 0x01>;
			power-domains = <0xba 0x04>;
			clocks = <0xba 0x06 0xba 0x4d 0xba 0x4c 0xba 0x0c 0xba 0x09 0xba 0x0a>;
			clock-names = "camnoc_axi", "soc_ahb", "slow_ahb_src", "cpas_ahb", "cci", "cci_src";
			pinctrl-0 = <0xc0>;
			pinctrl-1 = <0xc1>;
			pinctrl-names = "default", "sleep";
			status = "disabled";
			#address-cells = <0x01>;
			#size-cells = <0x00>;

			i2c-bus@0 {
				reg = <0x00>;
				clock-frequency = <0xf4240>;
				#address-cells = <0x01>;
				#size-cells = <0x00>;
			};

			i2c-bus@1 {
				reg = <0x01>;
				clock-frequency = <0xf4240>;
				#address-cells = <0x01>;
				#size-cells = <0x00>;
			};
		};

		clock-controller@ad00000 {
			compatible = "qcom,sc7180-camcc";
			reg = <0x00 0xad00000 0x00 0x10000>;
			clocks = <0x2f 0x00 0x32 0x0a 0x32 0x0d>;
			clock-names = "bi_tcxo", "iface", "xo";
			#clock-cells = <0x01>;
			#reset-cells = <0x01>;
			#power-domain-cells = <0x01>;
			phandle = <0xba>;
		};

		display-subsystem@ae00000 {
			compatible = "qcom,sc7180-mdss";
			reg = <0x00 0xae00000 0x00 0x1000>;
			reg-names = "mdss";
			power-domains = <0xc2 0x00>;
			clocks = <0x32 0x17 0xc2 0x02 0xc2 0x14>;
			clock-names = "iface", "ahb", "core";
			interrupts = <0x00 0x53 0x04>;
			interrupt-controller;
			#interrupt-cells = <0x01>;
			interconnects = <0xb7 0x04 0x07 0x06 0x01 0x07 0x05 0x00 0x07 0x36 0x12 0x07>;
			interconnect-names = "mdp0-mem", "cpu-cfg";
			iommus = <0x34 0x800 0x02>;
			#address-cells = <0x02>;
			#size-cells = <0x02>;
			ranges;
			status = "okay";
			phandle = <0xc4>;

			display-controller@ae01000 {
				compatible = "qcom,sc7180-dpu";
				reg = <0x00 0xae01000 0x00 0x8f000 0x00 0xaeb0000 0x00 0x2008>;
				reg-names = "mdp", "vbif";
				clocks = <0x32 0x1a 0xc2 0x02 0xc2 0x1a 0xc2 0x16 0xc2 0x14 0xc2 0x1e>;
				clock-names = "bus", "iface", "rot", "lut", "core", "vsync";
				assigned-clocks = <0xc2 0x1e 0xc2 0x1a 0xc2 0x02>;
				assigned-clock-rates = <0x124f800 0x124f800 0x124f800>;
				operating-points-v2 = <0xc3>;
				power-domains = <0x31 0x00>;
				interrupt-parent = <0xc4>;
				interrupts = <0x00>;

				ports {
					#address-cells = <0x01>;
					#size-cells = <0x00>;

					port@0 {
						reg = <0x00>;

						endpoint {
							remote-endpoint = <0xc5>;
							phandle = <0xc9>;
						};
					};

					port@2 {
						reg = <0x02>;

						endpoint {
							remote-endpoint = <0xc6>;
							phandle = <0xd3>;
						};
					};
				};

				opp-table {
					compatible = "operating-points-v2";
					phandle = <0xc3>;

					opp-200000000 {
						opp-hz = <0x00 0xbebc200>;
						required-opps = <0x21>;
					};

					opp-300000000 {
						opp-hz = <0x00 0x11e1a300>;
						required-opps = <0x22>;
					};

					opp-345000000 {
						opp-hz = <0x00 0x14904840>;
						required-opps = <0xb8>;
					};

					opp-460000000 {
						opp-hz = <0x00 0x1b6b0b00>;
						required-opps = <0x23>;
					};
				};
			};

			dsi@ae94000 {
				compatible = "qcom,sc7180-dsi-ctrl", "qcom,mdss-dsi-ctrl";
				reg = <0x00 0xae94000 0x00 0x400>;
				reg-names = "dsi_ctrl";
				interrupt-parent = <0xc4>;
				interrupts = <0x04>;
				clocks = <0xc2 0x04 0xc2 0x07 0xc2 0x18 0xc2 0x12 0xc2 0x02 0x32 0x1a>;
				clock-names = "byte", "byte_intf", "pixel", "core", "iface", "bus";
				assigned-clocks = <0xc2 0x05 0xc2 0x19>;
				assigned-clock-parents = <0xc7 0x00 0xc7 0x01>;
				operating-points-v2 = <0xc8>;
				power-domains = <0x31 0x00>;
				phys = <0xc7>;
				#address-cells = <0x01>;
				#size-cells = <0x00>;
				status = "okay";
				vdda-supply = <0x73>;

				ports {
					#address-cells = <0x01>;
					#size-cells = <0x00>;

					port@0 {
						reg = <0x00>;

						endpoint {
							remote-endpoint = <0xc9>;
							phandle = <0xc5>;
						};
					};

					port@1 {
						reg = <0x01>;

						endpoint {
							remote-endpoint = <0xca>;
							data-lanes = <0x00 0x01 0x02 0x03>;
							phandle = <0xd1>;
						};
					};
				};

				opp-table {
					compatible = "operating-points-v2";
					phandle = <0xc8>;

					opp-187500000 {
						opp-hz = <0x00 0xb2d05e0>;
						required-opps = <0x21>;
					};

					opp-300000000 {
						opp-hz = <0x00 0x11e1a300>;
						required-opps = <0x22>;
					};

					opp-358000000 {
						opp-hz = <0x00 0x1556a580>;
						required-opps = <0xb8>;
					};
				};

				panel@0 {
					reg = <0x00>;
					pinctrl-names = "default", "sleep";
					pinctrl-0 = <0xcb 0xcc>;
					pinctrl-1 = <0xcd 0xce>;
					vddio-supply = <0xcf>;
					vci-supply = <0xd0>;
					reset-gpios = <0x48 0x08 0x01>;
					status = "okay";
					compatible = "samsung,s6e3fc3-ams646yd04", "samsung,s6e3fc3";

					port {

						endpoint {
							remote-endpoint = <0xd1>;
							phandle = <0xca>;
						};
					};
				};
			};

			phy@ae94400 {
				compatible = "qcom,dsi-phy-10nm";
				reg = <0x00 0xae94400 0x00 0x200 0x00 0xae94600 0x00 0x280 0x00 0xae94a00 0x00 0x1e0>;
				reg-names = "dsi_phy", "dsi_phy_lane", "dsi_pll";
				#clock-cells = <0x01>;
				#phy-cells = <0x00>;
				clocks = <0xc2 0x02 0x2f 0x00>;
				clock-names = "iface", "ref";
				status = "okay";
				vdds-supply = <0x72>;
				phandle = <0xc7>;
			};

			displayport-controller@ae90000 {
				compatible = "qcom,sc7180-dp";
				status = "disabled";
				reg = <0x00 0xae90000 0x00 0x200 0x00 0xae90200 0x00 0x200 0x00 0xae90400 0x00 0xc00 0x00 0xae91000 0x00 0x400 0x00 0xae91400 0x00 0x400>;
				interrupt-parent = <0xc4>;
				interrupts = <0x0c>;
				clocks = <0xc2 0x02 0xc2 0x08 0xc2 0x0c 0xc2 0x0f 0xc2 0x10>;
				clock-names = "core_iface", "core_aux", "ctrl_link", "ctrl_link_iface", "stream_pixel";
				assigned-clocks = <0xc2 0x0d 0xc2 0x11>;
				assigned-clock-parents = <0xb3 0x01 0xb3 0x02>;
				phys = <0xb3 0x01>;
				phy-names = "dp";
				operating-points-v2 = <0xd2>;
				power-domains = <0x31 0x00>;
				#sound-dai-cells = <0x00>;

				ports {
					#address-cells = <0x01>;
					#size-cells = <0x00>;

					port@0 {
						reg = <0x00>;

						endpoint {
							remote-endpoint = <0xd3>;
							phandle = <0xc6>;
						};
					};

					port@1 {
						reg = <0x01>;

						endpoint {
						};
					};
				};

				opp-table {
					compatible = "operating-points-v2";
					phandle = <0xd2>;

					opp-160000000 {
						opp-hz = <0x00 0x9896800>;
						required-opps = <0x21>;
					};

					opp-270000000 {
						opp-hz = <0x00 0x1017df80>;
						required-opps = <0x22>;
					};

					opp-540000000 {
						opp-hz = <0x00 0x202fbf00>;
						required-opps = <0xb8>;
					};

					opp-810000000 {
						opp-hz = <0x00 0x30479e80>;
						required-opps = <0x23>;
					};
				};
			};
		};

		clock-controller@af00000 {
			compatible = "qcom,sc7180-dispcc";
			reg = <0x00 0xaf00000 0x00 0x200000>;
			clocks = <0x2f 0x00 0x32 0x18 0xc7 0x00 0xc7 0x01 0xb3 0x01 0xb3 0x02>;
			clock-names = "bi_tcxo", "gcc_disp_gpll0_clk_src", "dsi0_phy_pll_out_byteclk", "dsi0_phy_pll_out_dsiclk", "dp_phy_pll_link_clk", "dp_phy_pll_vco_div_clk";
			#clock-cells = <0x01>;
			#reset-cells = <0x01>;
			#power-domain-cells = <0x01>;
			phandle = <0xc2>;
		};

		interrupt-controller@b220000 {
			compatible = "qcom,sc7180-pdc", "qcom,pdc";
			reg = <0x00 0xb220000 0x00 0x30000>;
			qcom,pdc-ranges = <0x00 0x1e0 0x5e 0x5e 0x261 0x1f 0x7d 0x3f 0x01>;
			#interrupt-cells = <0x02>;
			interrupt-parent = <0x01>;
			interrupt-controller;
			phandle = <0x79>;
		};

		reset-controller@b2e0000 {
			compatible = "qcom,sc7180-pdc-global", "qcom,sdm845-pdc-global";
			reg = <0x00 0xb2e0000 0x00 0x20000>;
			#reset-cells = <0x01>;
		};

		thermal-sensor@c263000 {
			compatible = "qcom,sc7180-tsens", "qcom,tsens-v2";
			reg = <0x00 0xc263000 0x00 0x1ff 0x00 0xc222000 0x00 0x1ff>;
			#qcom,sensors = <0x0f>;
			interrupts = <0x00 0x1fa 0x04 0x00 0x1fc 0x04>;
			interrupt-names = "uplow", "critical";
			#thermal-sensor-cells = <0x01>;
			phandle = <0xf9>;
		};

		thermal-sensor@c265000 {
			compatible = "qcom,sc7180-tsens", "qcom,tsens-v2";
			reg = <0x00 0xc265000 0x00 0x1ff 0x00 0xc223000 0x00 0x1ff>;
			#qcom,sensors = <0x0a>;
			interrupts = <0x00 0x1fb 0x04 0x00 0x1fd 0x04>;
			interrupt-names = "uplow", "critical";
			#thermal-sensor-cells = <0x01>;
			phandle = <0x111>;
		};

		reset-controller@c2a0000 {
			compatible = "qcom,sc7180-aoss-cc", "qcom,sdm845-aoss-cc";
			reg = <0x00 0xc2a0000 0x00 0x31000>;
			#reset-cells = <0x01>;
		};

		power-management@c300000 {
			compatible = "qcom,sc7180-aoss-qmp", "qcom,aoss-qmp";
			reg = <0x00 0xc300000 0x00 0x400>;
			interrupts = <0x00 0x185 0x01>;
			mboxes = <0x2e 0x00>;
			#clock-cells = <0x00>;
			phandle = <0x76>;
		};

		sram@c3f0000 {
			compatible = "qcom,rpmh-stats";
			reg = <0x00 0xc3f0000 0x00 0x400>;
		};

		spmi@c440000 {
			compatible = "qcom,spmi-pmic-arb";
			reg = <0x00 0xc440000 0x00 0x1100 0x00 0xc600000 0x00 0x2000000 0x00 0xe600000 0x00 0x100000 0x00 0xe700000 0x00 0xa0000 0x00 0xc40a000 0x00 0x26000>;
			reg-names = "core", "chnls", "obsrvr", "intr", "cnfg";
			interrupt-names = "periph_irq";
			interrupts-extended = <0x79 0x01 0x04>;
			qcom,ee = <0x00>;
			qcom,channel = <0x00>;
			#address-cells = <0x02>;
			#size-cells = <0x00>;
			interrupt-controller;
			#interrupt-cells = <0x04>;

			pmic@0 {
				compatible = "qcom,pm6150", "qcom,spmi-pmic";
				reg = <0x00 0x00>;
				#address-cells = <0x01>;
				#size-cells = <0x00>;

				pon@800 {
					compatible = "qcom,pm8998-pon";
					reg = <0x800>;
					mode-bootloader = <0x15>;
					mode-recovery = <0x01>;

					pwrkey {
						compatible = "qcom,pm8941-pwrkey";
						interrupts = <0x00 0x08 0x00 0x03>;
						debounce = <0x3d09>;
						bias-pull-up;
						linux,code = <0x74>;
					};

					resin {
						compatible = "qcom,pm8941-resin";
						interrupts = <0x00 0x08 0x01 0x03>;
						debounce = <0x3d09>;
						bias-pull-up;
						status = "okay";
						linux,code = <0x72>;
					};
				};

				usb-vbus-regulator@1100 {
					compatible = "qcom,pm6150-vbus-reg", "qcom,pm8150b-vbus-reg";
					reg = <0x1100>;
					status = "disabled";
				};

				typec@1500 {
					compatible = "qcom,pm6150-typec", "qcom,pm8150b-typec";
					reg = <0x1500 0x1700>;
					interrupts = <0x00 0x15 0x00 0x01 0x00 0x15 0x01 0x03 0x00 0x15 0x02 0x01 0x00 0x15 0x03 0x03 0x00 0x15 0x04 0x01 0x00 0x15 0x05 0x01 0x00 0x15 0x06 0x03 0x00 0x15 0x07 0x01 0x00 0x17 0x00 0x01 0x00 0x17 0x01 0x01 0x00 0x17 0x02 0x01 0x00 0x17 0x03 0x01 0x00 0x17 0x04 0x01 0x00 0x17 0x05 0x01 0x00 0x17 0x06 0x01 0x00 0x17 0x07 0x01>;
					interrupt-names = "or-rid-detect-change", "vpd-detect", "cc-state-change", "vconn-oc", "vbus-change", "attach-detach", "legacy-cable-detect", "try-snk-src-detect", "sig-tx", "sig-rx", "msg-tx", "msg-rx", "msg-tx-failed", "msg-tx-discarded", "msg-rx-discarded", "fr-swap";
					status = "disabled";
				};

				temp-alarm@2400 {
					compatible = "qcom,spmi-temp-alarm";
					reg = <0x2400>;
					interrupts = <0x00 0x24 0x00 0x01>;
					io-channels = <0xd4 0x06>;
					io-channel-names = "thermal";
					#thermal-sensor-cells = <0x00>;
					phandle = <0x112>;
				};

				adc@3100 {
					compatible = "qcom,spmi-adc5";
					reg = <0x3100>;
					interrupts = <0x00 0x31 0x00 0x01>;
					#address-cells = <0x01>;
					#size-cells = <0x00>;
					#io-channel-cells = <0x01>;
					phandle = <0xd4>;

					channel@6 {
						reg = <0x06>;
						label = "die_temp";
					};
				};

				adc-tm@3500 {
					compatible = "qcom,spmi-adc-tm5";
					reg = <0x3500>;
					interrupts = <0x00 0x35 0x00 0x01>;
					#thermal-sensor-cells = <0x01>;
					#address-cells = <0x01>;
					#size-cells = <0x00>;
					status = "disabled";
				};

				rtc@6000 {
					compatible = "qcom,pm8941-rtc";
					reg = <0x6000 0x6100>;
					reg-names = "rtc", "alarm";
					interrupts = <0x00 0x61 0x01 0x01>;
					status = "okay";
				};

				gpio@c000 {
					compatible = "qcom,pm6150-gpio", "qcom,spmi-gpio";
					reg = <0xc000>;
					gpio-controller;
					gpio-ranges = <0xd5 0x00 0x00 0x0a>;
					#gpio-cells = <0x02>;
					interrupt-controller;
					#interrupt-cells = <0x02>;
					phandle = <0xd5>;

					hall-sensor-default-state {
						pins = "gpio10";
						function = "normal";
						output-disable;
						bias-disable;
						power-source = <0x00>;
						phandle = <0x115>;
					};
				};
			};

			pmic@1 {
				compatible = "qcom,pm6150", "qcom,spmi-pmic";
				reg = <0x01 0x00>;
				#address-cells = <0x01>;
				#size-cells = <0x00>;
			};

			pmic@4 {
				compatible = "qcom,pm6150l", "qcom,spmi-pmic";
				reg = <0x04 0x00>;
				#address-cells = <0x01>;
				#size-cells = <0x00>;

				temp-alarm@2400 {
					compatible = "qcom,spmi-temp-alarm";
					reg = <0x2400>;
					interrupts = <0x04 0x24 0x00 0x03>;
					#thermal-sensor-cells = <0x00>;
					phandle = <0x113>;
				};

				adc@3100 {
					compatible = "qcom,spmi-adc5";
					reg = <0x3100>;
					interrupts = <0x04 0x31 0x00 0x01>;
					#address-cells = <0x01>;
					#size-cells = <0x00>;
					#io-channel-cells = <0x01>;

					channel@0 {
						reg = <0x00>;
						qcom,pre-scaling = <0x01 0x01>;
						label = "ref_gnd";
					};

					channel@1 {
						reg = <0x01>;
						qcom,pre-scaling = <0x01 0x01>;
						label = "vref_1p25";
					};

					channel@6 {
						reg = <0x06>;
						qcom,pre-scaling = <0x01 0x01>;
						label = "die_temp";
					};

					channel@83 {
						reg = <0x83>;
						qcom,pre-scaling = <0x01 0x03>;
						label = "vph_pwr";
					};
				};

				adc-tm@3500 {
					compatible = "qcom,spmi-adc-tm5";
					reg = <0x3500>;
					interrupts = <0x04 0x35 0x00 0x01>;
					#thermal-sensor-cells = <0x01>;
					#address-cells = <0x01>;
					#size-cells = <0x00>;
					status = "disabled";
				};

				gpio@c000 {
					compatible = "qcom,pm6150l-gpio", "qcom,spmi-gpio";
					reg = <0xc000>;
					gpio-controller;
					gpio-ranges = <0xd6 0x00 0x00 0x0c>;
					#gpio-cells = <0x02>;
					interrupt-controller;
					#interrupt-cells = <0x02>;
					phandle = <0xd6>;

					key-vol-up-default-state {
						pins = "gpio8";
						function = "normal";
						input-enable;
						bias-pull-up;
						power-source = <0x00>;
						phandle = <0x114>;
					};
				};
			};

			pmic@5 {
				compatible = "qcom,pm6150l", "qcom,spmi-pmic";
				reg = <0x05 0x00>;
				#address-cells = <0x01>;
				#size-cells = <0x00>;

				led-controller@d300 {
					compatible = "qcom,pm6150l-flash-led", "qcom,spmi-flash-led";
					reg = <0xd300>;
					status = "disabled";
				};

				pwm {
					compatible = "qcom,pm6150l-lpg", "qcom,pm8150l-lpg";
					#address-cells = <0x01>;
					#size-cells = <0x00>;
					#pwm-cells = <0x02>;
					status = "disabled";
				};

				leds@d800 {
					compatible = "qcom,pm6150l-wled";
					reg = <0xd800 0xd900>;
					interrupts = <0x05 0xd8 0x01 0x01 0x05 0xd8 0x02 0x01>;
					interrupt-names = "ovp", "short";
					label = "backlight";
					status = "disabled";
				};
			};
		};

		sram@146aa000 {
			compatible = "qcom,sc7180-imem", "syscon", "simple-mfd";
			reg = <0x00 0x146aa000 0x00 0x2000>;
			#address-cells = <0x01>;
			#size-cells = <0x01>;
			ranges = <0x00 0x00 0x146aa000 0x2000>;

			pil-reloc@94c {
				compatible = "qcom,pil-reloc-info";
				reg = <0x94c 0xc8>;
			};
		};

		iommu@15000000 {
			compatible = "qcom,sc7180-smmu-500", "arm,mmu-500";
			reg = <0x00 0x15000000 0x00 0x100000>;
			#iommu-cells = <0x02>;
			#global-interrupts = <0x01>;
			interrupts = <0x00 0x41 0x04 0x00 0x5e 0x04 0x00 0x5f 0x04 0x00 0x60 0x04 0x00 0x61 0x04 0x00 0x62 0x04 0x00 0x63 0x04 0x00 0x64 0x04 0x00 0x65 0x04 0x00 0x66 0x04 0x00 0x67 0x04 0x00 0x68 0x04 0x00 0x69 0x04 0x00 0x6a 0x04 0x00 0x6b 0x04 0x00 0x6c 0x04 0x00 0x6d 0x04 0x00 0x6e 0x04 0x00 0x6f 0x04 0x00 0x70 0x04 0x00 0x71 0x04 0x00 0x72 0x04 0x00 0x73 0x04 0x00 0x74 0x04 0x00 0x75 0x04 0x00 0x76 0x04 0x00 0xb5 0x04 0x00 0xb6 0x04 0x00 0xb7 0x04 0x00 0xb8 0x04 0x00 0xb9 0x04 0x00 0xba 0x04 0x00 0xbb 0x04 0x00 0xbc 0x04 0x00 0xbd 0x04 0x00 0xbe 0x04 0x00 0xbf 0x04 0x00 0xc0 0x04 0x00 0x13b 0x04 0x00 0x13c 0x04 0x00 0x13d 0x04 0x00 0x13e 0x04 0x00 0x13f 0x04 0x00 0x140 0x04 0x00 0x141 0x04 0x00 0x142 0x04 0x00 0x143 0x04 0x00 0x144 0x04 0x00 0x145 0x04 0x00 0x146 0x04 0x00 0x147 0x04 0x00 0x148 0x04 0x00 0x149 0x04 0x00 0x14a 0x04 0x00 0x14b 0x04 0x00 0x14c 0x04 0x00 0x14d 0x04 0x00 0x14e 0x04 0x00 0x14f 0x04 0x00 0x150 0x04 0x00 0x151 0x04 0x00 0x152 0x04 0x00 0x153 0x04 0x00 0x154 0x04 0x00 0x155 0x04 0x00 0x156 0x04 0x00 0x157 0x04 0x00 0x158 0x04 0x00 0x159 0x04 0x00 0x191 0x04 0x00 0x192 0x04 0x00 0x193 0x04 0x00 0x194 0x04 0x00 0x195 0x04 0x00 0x196 0x04 0x00 0x197 0x04 0x00 0x198 0x04 0x00 0x199 0x04 0x00 0x19a 0x04 0x00 0x19b 0x04 0x00 0x19c 0x04>;
			phandle = <0x34>;
		};

		interrupt-controller@17a00000 {
			compatible = "arm,gic-v3";
			#address-cells = <0x02>;
			#size-cells = <0x02>;
			ranges;
			#interrupt-cells = <0x03>;
			interrupt-controller;
			reg = <0x00 0x17a00000 0x00 0x10000 0x00 0x17a60000 0x00 0x100000>;
			interrupts = <0x01 0x09 0x04>;
			phandle = <0x01>;

			msi-controller@17a40000 {
				compatible = "arm,gic-v3-its";
				msi-controller;
				#msi-cells = <0x01>;
				reg = <0x00 0x17a40000 0x00 0x20000>;
				status = "disabled";
			};
		};

		mailbox@17c00000 {
			compatible = "qcom,sc7180-apss-shared", "qcom,sdm845-apss-shared";
			reg = <0x00 0x17c00000 0x00 0x10000>;
			#mbox-cells = <0x01>;
			phandle = <0x2e>;
		};

		watchdog@17c10000 {
			compatible = "qcom,apss-wdt-sc7180", "qcom,kpss-wdt";
			reg = <0x00 0x17c10000 0x00 0x1000>;
			clocks = <0x30>;
			interrupts = <0x00 0x00 0x01>;
		};

		timer@17c20000 {
			#address-cells = <0x01>;
			#size-cells = <0x01>;
			ranges = <0x00 0x00 0x00 0x20000000>;
			compatible = "arm,armv7-timer-mem";
			reg = <0x00 0x17c20000 0x00 0x1000>;

			frame@17c21000 {
				frame-number = <0x00>;
				interrupts = <0x00 0x08 0x04 0x00 0x06 0x04>;
				reg = <0x17c21000 0x1000 0x17c22000 0x1000>;
			};

			frame@17c23000 {
				frame-number = <0x01>;
				interrupts = <0x00 0x09 0x04>;
				reg = <0x17c23000 0x1000>;
				status = "disabled";
			};

			frame@17c25000 {
				frame-number = <0x02>;
				interrupts = <0x00 0x0a 0x04>;
				reg = <0x17c25000 0x1000>;
				status = "disabled";
			};

			frame@17c27000 {
				frame-number = <0x03>;
				interrupts = <0x00 0x0b 0x04>;
				reg = <0x17c27000 0x1000>;
				status = "disabled";
			};

			frame@17c29000 {
				frame-number = <0x04>;
				interrupts = <0x00 0x0c 0x04>;
				reg = <0x17c29000 0x1000>;
				status = "disabled";
			};

			frame@17c2b000 {
				frame-number = <0x05>;
				interrupts = <0x00 0x0d 0x04>;
				reg = <0x17c2b000 0x1000>;
				status = "disabled";
			};

			frame@17c2d000 {
				frame-number = <0x06>;
				interrupts = <0x00 0x0e 0x04>;
				reg = <0x17c2d000 0x1000>;
				status = "disabled";
			};
		};

		rsc@18200000 {
			compatible = "qcom,rpmh-rsc";
			reg = <0x00 0x18200000 0x00 0x10000 0x00 0x18210000 0x00 0x10000 0x00 0x18220000 0x00 0x10000>;
			reg-names = "drv-0", "drv-1", "drv-2";
			interrupts = <0x00 0x03 0x04 0x00 0x04 0x04 0x00 0x05 0x04>;
			qcom,tcs-offset = <0xd00>;
			qcom,drv-id = <0x02>;
			qcom,tcs-config = <0x02 0x02 0x00 0x03 0x01 0x03 0x03 0x01>;
			power-domains = <0x24>;

			clock-controller {
				compatible = "qcom,sc7180-rpmh-clk";
				clocks = <0xd7>;
				clock-names = "xo";
				#clock-cells = <0x01>;
				phandle = <0x2f>;
			};

			power-controller {
				compatible = "qcom,sc7180-rpmhpd";
				#power-domain-cells = <0x01>;
				operating-points-v2 = <0xd8>;
				phandle = <0x31>;

				opp-table {
					compatible = "operating-points-v2";
					phandle = <0xd8>;

					opp1 {
						opp-level = <0x10>;
					};

					opp2 {
						opp-level = <0x30>;
					};

					opp3 {
						opp-level = <0x40>;
						phandle = <0x21>;
					};

					opp4 {
						opp-level = <0x80>;
						phandle = <0x22>;
					};

					opp5 {
						opp-level = <0xc0>;
						phandle = <0xb8>;
					};

					opp6 {
						opp-level = <0xe0>;
					};

					opp7 {
						opp-level = <0x100>;
						phandle = <0x23>;
					};

					opp8 {
						opp-level = <0x140>;
					};

					opp9 {
						opp-level = <0x150>;
					};

					opp10 {
						opp-level = <0x180>;
						phandle = <0xb9>;
					};

					opp11 {
						opp-level = <0x1a0>;
					};
				};
			};

			bcm-voter {
				compatible = "qcom,bcm-voter";
				phandle = <0x6c>;
			};

			pm6150-rpmh-regulators {
				compatible = "qcom,pm6150-rpmh-regulators";
				qcom,pmic-id = "a";

				smps1 {
					regulator-min-microvolt = <0x113640>;
					regulator-max-microvolt = <0x113640>;
				};

				smps4 {
					regulator-min-microvolt = <0xc92c0>;
					regulator-max-microvolt = <0x111700>;
				};

				smps5 {
					regulator-min-microvolt = <0x1a9c80>;
					regulator-max-microvolt = <0x1f20c0>;
				};

				ldo1 {
					regulator-min-microvolt = <0x11f990>;
					regulator-max-microvolt = <0x132a40>;
					regulator-initial-mode = <0x03>;
				};

				ldo2 {
					regulator-min-microvolt = <0xe6780>;
					regulator-max-microvolt = <0x101d00>;
					regulator-initial-mode = <0x03>;
				};

				ldo3 {
					regulator-min-microvolt = <0xec540>;
					regulator-max-microvolt = <0x103c40>;
					regulator-initial-mode = <0x03>;
				};

				ldo4 {
					regulator-min-microvolt = <0xc92c0>;
					regulator-max-microvolt = <0xe2900>;
					regulator-initial-mode = <0x03>;
					regulator-allow-set-load;
					regulator-allowed-modes = <0x01 0x03>;
					phandle = <0x72>;
				};

				ldo5 {
					regulator-min-microvolt = <0x261600>;
					regulator-max-microvolt = <0x2dc6c0>;
					regulator-initial-mode = <0x03>;
				};

				ldo6 {
					regulator-min-microvolt = <0x8aac0>;
					regulator-max-microvolt = <0x9e340>;
					regulator-initial-mode = <0x03>;
				};

				ldo9 {
					regulator-min-microvolt = <0x77240>;
					regulator-max-microvolt = "", "\f5";
					regulator-initial-mode = <0x03>;
					phandle = <0xda>;
				};

				ldo10 {
					regulator-min-microvolt = <0x1b7740>;
					regulator-max-microvolt = <0x1bf440>;
					regulator-initial-mode = <0x03>;
					phandle = <0x4a>;
				};

				ldo11 {
					regulator-min-microvolt = <0x19e100>;
					regulator-max-microvolt = <0x1d0d80>;
					regulator-initial-mode = <0x03>;
					phandle = <0x33>;
				};

				ldo12 {
					regulator-min-microvolt = <0x19e100>;
					regulator-max-microvolt = <0x1dc900>;
					regulator-initial-mode = <0x03>;
					regulator-allow-set-load;
					regulator-allowed-modes = <0x01 0x03>;
					phandle = <0x70>;
				};

				ldo13 {
					regulator-min-microvolt = <0x19e100>;
					regulator-max-microvolt = <0x1d0d80>;
					regulator-initial-mode = <0x03>;
					phandle = <0xcf>;
				};

				ldo14 {
					regulator-min-microvolt = <0x1a5e00>;
					regulator-max-microvolt = <0x1bf440>;
					regulator-initial-mode = <0x03>;
				};

				ldo15 {
					regulator-min-microvolt = <0x19e100>;
					regulator-max-microvolt = <0x1d0d80>;
					regulator-initial-mode = <0x03>;
					phandle = <0x119>;
				};

				ldo16 {
					regulator-min-microvolt = <0x261600>;
					regulator-max-microvolt = <0x326a40>;
					regulator-initial-mode = <0x03>;
				};

				ldo17 {
					regulator-min-microvolt = <0x2c8e40>;
					regulator-max-microvolt = "", "1Q";
					regulator-initial-mode = <0x03>;
					phandle = <0xaf>;
				};

				ldo18 {
					regulator-min-microvolt = <0x261600>;
					regulator-max-microvolt = <0x326a40>;
					regulator-initial-mode = <0x03>;
					phandle = <0xd0>;
				};

				ldo19 {
					regulator-min-microvolt = <0x292340>;
					regulator-max-microvolt = <0x326a40>;
					regulator-initial-mode = <0x03>;
					regulator-allow-set-load;
					regulator-allowed-modes = <0x01 0x03>;
					phandle = <0x6f>;
				};
			};

			pm6150l-rpmh-regulators {
				compatible = "qcom,pm6150l-rpmh-regulators";
				qcom,pmic-id = "c";

				smps8 {
					regulator-min-microvolt = <0x111700>;
					regulator-max-microvolt = <0x157c00>;
				};

				ldo1 {
					regulator-min-microvolt = <0x18a880>;
					regulator-max-microvolt = <0x1e4600>;
					regulator-initial-mode = <0x03>;
					phandle = <0x4b>;
				};

				ldo2 {
					regulator-min-microvolt = <0x11d280>;
					regulator-max-microvolt = <0x13e5c0>;
					regulator-initial-mode = <0x03>;
					phandle = <0x4c>;
				};

				ldo3 {
					regulator-min-microvolt = <0x1174c0>;
					regulator-max-microvolt = <0x13e5c0>;
					regulator-initial-mode = <0x03>;
					regulator-allow-set-load;
					regulator-allowed-modes = <0x01 0x03>;
					phandle = <0x73>;
				};

				ldo4 {
					regulator-min-microvolt = <0x192580>;
					regulator-max-microvolt = <0x326a40>;
					regulator-initial-mode = <0x03>;
				};

				ldo5 {
					regulator-min-microvolt = <0x192580>;
					regulator-max-microvolt = <0x326a40>;
					regulator-initial-mode = <0x03>;
				};

				ldo6 {
					regulator-min-microvolt = <0x192580>;
					regulator-max-microvolt = <0x326a40>;
					regulator-initial-mode = <0x03>;
					phandle = <0xac>;
				};

				ldo7 {
					regulator-min-microvolt = <0x2dc6c0>;
					regulator-max-microvolt = <0x2dc6c0>;
					regulator-initial-mode = <0x03>;
					phandle = <0x5c>;
				};

				ldo8 {
					regulator-min-microvolt = <0x1b7740>;
					regulator-max-microvolt = <0x1b7740>;
					regulator-initial-mode = <0x03>;
				};

				ldo9 {
					regulator-min-microvolt = <0x2d0b40>;
					regulator-max-microvolt = <0x326a40>;
					regulator-initial-mode = <0x03>;
					phandle = <0xab>;
				};

				ldo10 {
					regulator-min-microvolt = <0x2dc6c0>;
					regulator-max-microvolt = <0x33e140>;
					regulator-initial-mode = <0x03>;
					phandle = <0x4d>;
				};

				ldo11 {
					regulator-min-microvolt = <0x2dc6c0>;
					regulator-max-microvolt = <0x33e140>;
					regulator-initial-mode = <0x03>;
					phandle = <0xdb>;
				};

				bob {
					regulator-min-microvolt = <0x2de600>;
					regulator-max-microvolt = <0x3c6cc0>;
					regulator-initial-mode = <0x02>;
					phandle = <0x11a>;
				};
			};
		};

		interconnect@18321000 {
			compatible = "qcom,sc7180-osm-l3", "qcom,osm-l3";
			reg = <0x00 0x18321000 0x00 0x1400>;
			clocks = <0x2f 0x00 0x32 0x01>;
			clock-names = "xo", "alternate";
			#interconnect-cells = <0x01>;
			phandle = <0x07>;
		};

		cpufreq@18323000 {
			compatible = "qcom,sc7180-cpufreq-hw", "qcom,cpufreq-hw";
			reg = <0x00 0x18323000 0x00 0x1400 0x00 0x18325800 0x00 0x1400>;
			reg-names = "freq-domain0", "freq-domain1";
			clocks = <0x2f 0x00 0x32 0x01>;
			clock-names = "xo", "alternate";
			#freq-domain-cells = <0x01>;
			#clock-cells = <0x01>;
			phandle = <0x02>;
		};

		wifi@18800000 {
			compatible = "qcom,wcn3990-wifi";
			reg = <0x00 0x18800000 0x00 0x800000>;
			reg-names = "membase";
			iommus = <0x34 0xc0 0x01>;
			interrupts = <0x00 0x19e 0x04 0x00 0x19f 0x04 0x00 0x1a0 0x04 0x00 0x1a1 0x04 0x00 0x1a2 0x04 0x00 0x1a3 0x04 0x00 0x1a4 0x04 0x00 0x1a5 0x04 0x00 0x1a6 0x04 0x00 0x1a7 0x04 0x00 0x1a8 0x04 0x00 0x1a9 0x04>;
			memory-region = <0xd9>;
			qcom,msa-fixed-perm;
			status = "okay";
			vdd-0.8-cx-mx-supply = <0xda>;
			vdd-1.8-xo-supply = <0x4b>;
			vdd-1.3-rfa-supply = <0x4c>;
			vdd-3.3-ch0-supply = <0x4d>;
			vdd-3.3-ch1-supply = <0xdb>;
		};

		remoteproc@62400000 {
			compatible = "qcom,sc7180-adsp-pas";
			reg = <0x00 0x62400000 0x00 0x100>;
			interrupts-extended = <0x01 0x00 0xa2 0x01 0xdc 0x00 0x01 0xdc 0x01 0x01 0xdc 0x02 0x01 0xdc 0x03 0x01>;
			interrupt-names = "wdog", "fatal", "ready", "handover", "stop-ack";
			clocks = <0x2f 0x00>;
			clock-names = "xo";
			power-domains = <0x31 0x06 0x31 0x05>;
			power-domain-names = "lcx", "lmx";
			qcom,qmp = <0x76>;
			qcom,smem-states = <0xdd 0x00>;
			qcom,smem-state-names = "stop";
			status = "okay";
			memory-region = <0xde>;
			firmware-name = "qcom/sm7125/a52q/adsp.mbn";

			glink-edge {
				interrupts = <0x00 0x9c 0x01>;
				label = "lpass";
				qcom,remote-pid = <0x02>;
				mboxes = <0x2e 0x08>;

				apr {
					compatible = "qcom,apr-v2";
					qcom,glink-channels = "apr_audio_svc";
					qcom,domain = <0x04>;
					#address-cells = <0x01>;
					#size-cells = <0x00>;

					service@3 {
						compatible = "qcom,q6core";
						reg = <0x03>;
						qcom,protection-domain = "avs/audio", "msm/adsp/audio_pd";
					};

					service@4 {
						compatible = "qcom,q6afe";
						reg = <0x04>;
						qcom,protection-domain = "avs/audio", "msm/adsp/audio_pd";

						dais {
							compatible = "qcom,q6afe-dais";
							#address-cells = <0x01>;
							#size-cells = <0x00>;
							#sound-dai-cells = <0x01>;
							phandle = <0xee>;

							dai@113 {
								reg = <0x71>;
							};

							dai@120 {
								reg = <0x78>;
							};

							dai@127 {
								reg = <0x7f>;
								qcom,sd-lines = <0x00>;
							};
						};

						clock-controller {
							compatible = "qcom,q6afe-clocks";
							#clock-cells = <0x02>;
							phandle = <0xe2>;
						};
					};

					service@7 {
						compatible = "qcom,q6asm";
						reg = <0x07>;
						qcom,protection-domain = "avs/audio", "msm/adsp/audio_pd";

						dais {
							compatible = "qcom,q6asm-dais";
							#address-cells = <0x01>;
							#size-cells = <0x00>;
							#sound-dai-cells = <0x01>;
							iommus = <0x34 0x1001 0x00>;
							phandle = <0xed>;

							dai@0 {
								reg = <0x00>;
							};

							dai@1 {
								reg = <0x01>;
							};

							dai@2 {
								reg = <0x02>;
							};
						};
					};

					service@8 {
						compatible = "qcom,q6adm";
						reg = <0x08>;
						qcom,protection-domain = "avs/audio", "msm/adsp/audio_pd";

						routing {
							compatible = "qcom,q6adm-routing";
							#sound-dai-cells = <0x00>;
							phandle = <0xef>;
						};
					};
				};

				fastrpc {
					compatible = "qcom,fastrpc";
					qcom,glink-channels = "fastrpcglink-apps-dsp";
					label = "adsp";
					#address-cells = <0x01>;
					#size-cells = <0x00>;

					compute-cb@3 {
						compatible = "qcom,fastrpc-compute-cb";
						reg = <0x03>;
						iommus = <0x34 0x1003 0x00>;
					};

					compute-cb@4 {
						compatible = "qcom,fastrpc-compute-cb";
						reg = <0x04>;
						iommus = <0x34 0x1004 0x00>;
					};

					compute-cb@5 {
						compatible = "qcom,fastrpc-compute-cb";
						reg = <0x05>;
						iommus = <0x34 0x1005 0x00>;
						qcom,nsessions = <0x05>;
					};
				};
			};
		};

		clock-controller@62d00000 {
			compatible = "qcom,sc7180-lpasscorecc";
			reg = <0x00 0x62d00000 0x00 0x50000 0x00 0x62780000 0x00 0x30000>;
			reg-names = "lpass_core_cc", "lpass_audio_cc";
			clocks = <0x32 0x83 0x2f 0x00>;
			clock-names = "iface", "bi_tcxo";
			power-domains = <0xdf 0x00>;
			#clock-cells = <0x01>;
			#power-domain-cells = <0x01>;
			status = "reserved";
			phandle = <0xe0>;
		};

		lpass@62d87000 {
			compatible = "qcom,sc7180-lpass-cpu";
			reg = <0x00 0x62d87000 0x00 0x68000 0x00 0x62f00000 0x00 0x29000>;
			reg-names = "lpass-hdmiif", "lpass-lpaif";
			iommus = <0x34 0x1020 0x00 0x34 0x1021 0x00 0x34 0x1032 0x00>;
			power-domains = <0xdf 0x00>;
			required-opps = <0x23>;
			status = "disabled";
			clocks = <0x32 0x83 0xe0 0x06 0xe0 0x07 0xe0 0x0a 0xe0 0x08 0xe0 0x09>;
			clock-names = "pcnoc-sway-clk", "audio-core", "mclk0", "pcnoc-mport-clk", "mi2s-bit-clk0", "mi2s-bit-clk1";
			#sound-dai-cells = <0x01>;
			#address-cells = <0x01>;
			#size-cells = <0x00>;
			interrupts = <0x00 0xa0 0x04 0x00 0x10c 0x04>;
			interrupt-names = "lpass-irq-lpaif", "lpass-irq-hdmi";
		};

		clock-controller@63000000 {
			compatible = "qcom,sc7180-lpasshm";
			reg = <0x00 0x63000000 0x00 0x28>;
			clocks = <0x32 0x83 0x2f 0x00>;
			clock-names = "iface", "bi_tcxo";
			power-domains = <0x31 0x00>;
			#clock-cells = <0x01>;
			#power-domain-cells = <0x01>;
			status = "reserved";
			phandle = <0xdf>;
		};

		codec@62640000 {
			compatible = "qcom,sm8250-lpass-wsa-macro";
			reg = <0x00 0x62640000 0x00 0x1000>;
			status = "disabled";
			clocks = <0xe1 0x01 0xe1 0x00 0xe2 0x66 0x01 0xe2 0x67 0x01 0xe3 0x00 0xe4>;
			clock-names = "mclk", "npl", "macro", "dcodec", "va", "fsgen";
			#clock-cells = <0x00>;
			clock-frequency = <0x124f800>;
			clock-output-names = "mclk";
			#sound-dai-cells = <0x01>;
			pinctrl-names = "default";
			pinctrl-0 = <0xe5>;
			phandle = <0xe6>;
		};

		soundwire-controller@62650000 {
			reg = <0x00 0x62650000 0x00 0x2000>;
			compatible = "qcom,soundwire-v1.5.1";
			status = "disabled";
			interrupts = <0x00 0x127 0x04>;
			clocks = <0xe6>;
			clock-names = "iface";
			qcom,din-ports = <0x02>;
			qcom,dout-ports = <0x06>;
			qcom,ports-sinterval-low = <0x71f3f07 0x1f3f0f0f>;
			qcom,ports-offset1 = <0x1020c06 0x120d070a>;
			qcom,ports-offset2 = <0xff001fff 0x1f0000>;
			qcom,ports-block-pack-mode = <0x100 0x10000>;
			#sound-dai-cells = <0x01>;
			#address-cells = <0x02>;
			#size-cells = <0x00>;
		};

		clock-controller@62700000 {
			compatible = "qcom,sm8250-lpass-audiocc";
			reg = <0x00 0x62700000 0x00 0x30000>;
			#clock-cells = <0x01>;
			clocks = <0xe2 0x66 0x01 0xe2 0x67 0x01 0xe2 0x39 0x01>;
			clock-names = "core", "audio", "bus";
			phandle = <0xe1>;
		};

		codec@62770000 {
			compatible = "qcom,sm8250-lpass-va-macro";
			reg = <0x00 0x62770000 0x00 0x1000>;
			status = "okay";
			clocks = <0xe3 0x00 0xe2 0x66 0x01 0xe2 0x67 0x01>;
			clock-names = "mclk", "macro", "dcodec";
			#clock-cells = <0x00>;
			clock-frequency = <0x927c00>;
			clock-output-names = "fsgen";
			#sound-dai-cells = <0x01>;
			qcom,dmic-sample-rate = <0x927c0>;
			phandle = <0xe4>;
		};

		rxmacro@62600000 {
			pinctrl-names = "default";
			pinctrl-0 = <0xe7>;
			compatible = "qcom,sm8250-lpass-rx-macro";
			reg = <0x00 0x62600000 0x00 0x1000>;
			status = "okay";
			clocks = <0xe2 0x39 0x01 0xe2 0x3a 0x01 0xe2 0x66 0x01 0xe2 0x67 0x01 0xe4>;
			clock-names = "mclk", "npl", "macro", "dcodec", "fsgen";
			#clock-cells = <0x00>;
			clock-frequency = <0x927c00>;
			clock-output-names = "mclk";
			#sound-dai-cells = <0x01>;
			phandle = <0xe8>;
		};

		soundwire-controller@62610000 {
			reg = <0x00 0x62610000 0x00 0x2000>;
			compatible = "qcom,soundwire-v1.5.1";
			status = "okay";
			interrupts = <0x00 0x129 0x04>;
			clocks = <0xe8>;
			clock-names = "iface";
			label = "RX";
			qcom,din-ports = <0x00>;
			qcom,dout-ports = <0x05>;
			qcom,ports-sinterval-low = [03 1f 1f 07 00];
			qcom,ports-offset1 = [00 00 0b 01 00];
			qcom,ports-offset2 = [00 00 0b 00 00];
			qcom,ports-hstart = [ff 03 ff ff ff];
			qcom,ports-hstop = [ff 06 ff ff ff];
			qcom,ports-word-length = [01 07 04 ff ff];
			qcom,ports-block-pack-mode = [ff 00 01 ff ff];
			qcom,ports-block-group-count = [ff ff ff ff 00];
			qcom,ports-lane-control = [01 00 00 00 00];
			#sound-dai-cells = <0x01>;
			#address-cells = <0x02>;
			#size-cells = <0x00>;
			phandle = <0xf3>;

			wcd9380-rx@0,4 {
				compatible = "sdw20217010d00";
				reg = <0x00 0x04>;
				qcom,rx-port-mapping = <0x01 0x02 0x03 0x04 0x05>;
				phandle = <0x117>;
			};
		};

		txmacro@62620000 {
			pinctrl-names = "default";
			pinctrl-0 = <0xe9>;
			compatible = "qcom,sm8250-lpass-tx-macro";
			reg = <0x00 0x62620000 0x00 0x1000>;
			status = "okay";
			clocks = <0xe2 0x39 0x01 0xe2 0x3a 0x01 0xe2 0x66 0x01 0xe2 0x67 0x01 0xe4>;
			clock-names = "mclk", "npl", "macro", "dcodec", "fsgen";
			#clock-cells = <0x00>;
			clock-frequency = <0x927c00>;
			clock-output-names = "mclk";
			#address-cells = <0x02>;
			#size-cells = <0x02>;
			#sound-dai-cells = <0x01>;
			phandle = <0xea>;
		};

		soundwire-controller@62630000 {
			reg = <0x00 0x62630000 0x00 0x2000>;
			compatible = "qcom,soundwire-v1.5.1";
			status = "okay";
			interrupts = <0x00 0x128 0x04>;
			clocks = <0xea>;
			clock-names = "iface";
			label = "TX";
			qcom,din-ports = <0x05>;
			qcom,dout-ports = <0x00>;
			qcom,ports-sinterval-low = [ff 01 01 03 03];
			qcom,ports-offset1 = [ff 01 00 02 00];
			qcom,ports-offset2 = [ff 00 00 00 00];
			qcom,ports-block-pack-mode = [ff ff ff ff ff];
			qcom,ports-hstart = [ff ff ff ff ff];
			qcom,ports-hstop = [ff ff ff ff ff];
			qcom,ports-word-length = [ff ff ff ff ff];
			qcom,ports-block-group-count = [ff ff ff ff ff];
			qcom,ports-lane-control = [ff 00 01 00 01];
			qcom,port-offset = <0x01>;
			#sound-dai-cells = <0x01>;
			#address-cells = <0x02>;
			#size-cells = <0x00>;
			phandle = <0xf4>;

			wcd9380-tx@0,3 {
				compatible = "sdw20217010d00";
				reg = <0x00 0x03>;
				qcom,tx-port-mapping = <0x02 0x03 0x04 0x05>;
				phandle = <0x118>;
			};
		};

		clock-controller@62780000 {
			compatible = "qcom,sm8250-lpass-aoncc";
			reg = <0x00 0x62780000 0x00 0x40000>;
			#clock-cells = <0x01>;
			clocks = <0xe2 0x66 0x01 0xe2 0x67 0x01 0xe2 0x3a 0x01>;
			clock-names = "core", "audio", "bus";
			phandle = <0xe3>;
		};

		pinctrl@627c0000 {
			compatible = "qcom,sm7125-lpass-lpi-pinctrl", "qcom,sc7280-lpass-lpi-pinctrl";
			reg = <0x00 0x627c0000 0x00 0x20000 0x00 0x62950000 0x00 0x10000>;
			gpio-controller;
			#gpio-cells = <0x02>;
			gpio-ranges = <0xeb 0x00 0x00 0x0f>;
			clocks = <0xe2 0x66 0x01 0xe2 0x67 0x01>;
			clock-names = "core", "audio";
			phandle = <0xeb>;

			i2s1-active-pins {
				phandle = <0xec>;

				clk {
					pins = "gpio6";
					function = "i2s1_clk";
					drive-strength = <0x08>;
					bias-disable;
					output-high;
				};

				ws {
					pins = "gpio7";
					function = "i2s1_ws";
					drive-strength = <0x08>;
					bias-disable;
					output-high;
				};

				data {
					pins = "gpio8", "gpio9";
					function = "i2s1_data";
					drive-strength = <0x08>;
					bias-disable;
					output-high;
				};
			};

			wsa-swr-active-pins {
				phandle = <0xe5>;

				clk {
					pins = "gpio10";
					function = "wsa_swr_clk";
					drive-strength = <0x0a>;
					slew-rate = <0x03>;
					bias-disable;
				};

				data {
					pins = "gpio11";
					function = "wsa_swr_data";
					drive-strength = <0x0a>;
					slew-rate = <0x03>;
					bias-bus-hold;
				};
			};

			rx_swr-active-pins {
				phandle = <0xe7>;

				clk {
					pins = "gpio3";
					function = "swr_rx_clk";
					drive-strength = <0x0a>;
					slew-rate = <0x03>;
					bias-disable;
				};

				data {
					pins = "gpio4", "gpio5";
					function = "swr_rx_data";
					drive-strength = <0x0a>;
					slew-rate = <0x03>;
					bias-bus-hold;
				};
			};

			tx_swr-active-pins {
				phandle = <0xe9>;

				clk {
					pins = "gpio0";
					function = "swr_tx_clk";
					drive-strength = <0x0a>;
					slew-rate = <0x03>;
					bias-disable;
				};

				data {
					pins = "gpio1", "gpio2", "gpio14";
					function = "swr_tx_data";
					drive-strength = <0x0a>;
					slew-rate = <0x03>;
					bias-bus-hold;
				};
			};
		};

		sound {
			compatible = "qcom,sm7125-sndcard";
			pinctrl-0 = <0xec>;
			pinctrl-names = "default";
			audio-routing = "IN1_HPHL", "HPHL_OUT", "IN2_HPHR", "HPHR_OUT", "AMIC1", "MIC BIAS1", "AMIC2", "MIC BIAS2", "AMIC4", "MIC BIAS3", "TX SWR_ADC0", "ADC1_OUTPUT", "TX SWR_ADC1", "ADC2_OUTPUT", "TX SWR_ADC3", "ADC4_OUTPUT";
			model = "Galaxy A52";

			mm1-dai-link {
				link-name = "MultiMedia1";

				cpu {
					sound-dai = <0xed 0x00>;
				};
			};

			mm2-dai-link {
				link-name = "MultiMedia2";

				cpu {
					sound-dai = <0xed 0x01>;
				};
			};

			mm3-dai-link {
				link-name = "MultiMedia3";

				cpu {
					sound-dai = <0xed 0x02>;
				};
			};

			i2s-dai-link {
				link-name = "I2S Playback";

				cpu {
					sound-dai = <0xee 0x7f>;
				};

				platform {
					sound-dai = <0xef>;
				};

				codec {
					sound-dai = <0xf0 0xf1>;
				};
			};

			wcd-playback-dai-link {
				link-name = "WCD Playback";

				cpu {
					sound-dai = <0xee 0x71>;
				};

				codec {
					sound-dai = <0xf2 0x00 0xf3 0x00 0xe8 0x00>;
				};

				platform {
					sound-dai = <0xef>;
				};
			};

			wcd-capture-dai-link {
				link-name = "WCD Capture";

				cpu {
					sound-dai = <0xee 0x78>;
				};

				codec {
					sound-dai = <0xf2 0x01 0xf4 0x00 0xea 0x00>;
				};

				platform {
					sound-dai = <0xef>;
				};
			};
		};

		remoteproc@8300000 {
			compatible = "qcom,sm7125-cdsp-pas", "qcom,sm6350-cdsp-pas";
			reg = <0x00 0x8300000 0x00 0x10000>;
			interrupts-extended = <0x01 0x00 0x242 0x04 0xf5 0x00 0x01 0xf5 0x01 0x01 0xf5 0x02 0x01 0xf5 0x03 0x01>;
			interrupt-names = "wdog", "fatal", "ready", "handover", "stop-ack";
			clocks = <0x2f 0x00>;
			clock-names = "xo";
			power-domains = <0x31 0x00 0x31 0x03>;
			power-domain-names = "cx", "mx";
			memory-region = <0xf6>;
			qcom,qmp = <0x76>;
			qcom,smem-states = <0xf7 0x00>;
			qcom,smem-state-names = "stop";
			status = "okay";
			firmware-name = "qcom/sm7125/a52q/cdsp.mbn";

			glink-edge {
				interrupts = <0x00 0x23e 0x01>;
				label = "cdsp";
				qcom,remote-pid = <0x05>;
				mboxes = <0x2e 0x04>;

				fastrpc {
					compatible = "qcom,fastrpc";
					qcom,glink-channels = "fastrpcglink-apps-dsp";
					label = "cdsp";
					#address-cells = <0x01>;
					#size-cells = <0x00>;

					compute-cb@1 {
						compatible = "qcom,fastrpc-compute-cb";
						reg = <0x01>;
						iommus = <0x34 0x1401 0x20>;
					};

					compute-cb@2 {
						compatible = "qcom,fastrpc-compute-cb";
						reg = <0x02>;
						iommus = <0x34 0x1402 0x20>;
					};

					compute-cb@3 {
						compatible = "qcom,fastrpc-compute-cb";
						reg = <0x03>;
						iommus = <0x34 0x1403 0x20>;
					};

					compute-cb@4 {
						compatible = "qcom,fastrpc-compute-cb";
						reg = <0x04>;
						iommus = <0x34 0x1404 0x20>;
					};

					compute-cb@5 {
						compatible = "qcom,fastrpc-compute-cb";
						reg = <0x05>;
						iommus = <0x34 0x1405 0x20>;
					};

					compute-cb@6 {
						compatible = "qcom,fastrpc-compute-cb";
						reg = <0x06>;
						iommus = <0x34 0x1406 0x20>;
					};

					compute-cb@7 {
						compatible = "qcom,fastrpc-compute-cb";
						reg = <0x07>;
						iommus = <0x34 0x1407 0x20>;
					};

					compute-cb@8 {
						compatible = "qcom,fastrpc-compute-cb";
						reg = <0x08>;
						iommus = <0x34 0x1408 0x20>;
					};
				};
			};
		};

		dma-controller@800000 {
			compatible = "qcom,sm7125-gpi-dma", "qcom,sm6350-gpi-dma";
			reg = <0x00 0x800000 0x00 0x60000>;
			interrupts = <0x00 0xf4 0x04 0x00 0xf5 0x04 0x00 0xf6 0x04 0x00 0xf7 0x04 0x00 0xf8 0x04 0x00 0xf9 0x04 0x00 0xfa 0x04 0x00 0xfb 0x04 0x00 0xfc 0x04 0x00 0xfd 0x04>;
			dma-channels = <0x0a>;
			dma-channel-mask = <0x1f>;
			iommus = <0x34 0x56 0x00>;
			#dma-cells = <0x03>;
			status = "okay";
		};

		dma-controller@a00000 {
			compatible = "qcom,sm7125-gpi-dma", "qcom,sm6350-gpi-dma";
			reg = <0x00 0xa00000 0x00 0x60000>;
			interrupts = <0x00 0x285 0x04 0x00 0x286 0x04 0x00 0x287 0x04 0x00 0x288 0x04 0x00 0x289 0x04 0x00 0x28a 0x04 0x00 0x28b 0x04 0x00 0x28c 0x04 0x00 0x28d 0x04 0x00 0x28e 0x04>;
			dma-channels = <0x0a>;
			dma-channel-mask = <0x3f>;
			iommus = <0x34 0x4d6 0x00>;
			#dma-cells = <0x03>;
			status = "okay";
			phandle = <0x5a>;
		};

		i2c-18 {
			compatible = "i2c-gpio";
			#address-cells = <0x01>;
			#size-cells = <0x00>;
			sda-gpios = <0x48 0x58 0x06>;
			scl-gpios = <0x48 0x59 0x06>;
			pinctrl-names = "default";
			pinctrl-0 = <0xf8>;
			i2c-gpio,delay-us = <0x02>;

			codec@4c {
				compatible = "ti,tas2562";
				reg = <0x4c>;
				#sound-dai-cells = <0x00>;
				interrupt-parent = <0x48>;
				interrupts = <0x5a 0x00>;
				shutdown-gpios = <0x48 0x5e 0x00>;
				sound-name-prefix = "Right";
				ti,vmon-slot-no = <0x01>;
				ti,imon-slot-no = <0x00>;
				phandle = <0xf0>;
			};

			codec@4d {
				compatible = "ti,tas2562";
				reg = <0x4d>;
				#sound-dai-cells = <0x00>;
				interrupt-parent = <0x48>;
				interrupts = <0x5a 0x00>;
				shutdown-gpios = <0x48 0x5e 0x00>;
				sound-name-prefix = "Left";
				ti,vmon-slot-no = <0x01>;
				ti,imon-slot-no = <0x00>;
				phandle = <0xf1>;
			};
		};
	};

	thermal-zones {

		cpu0-thermal {
			polling-delay-passive = <0xfa>;
			polling-delay = <0x00>;
			thermal-sensors = <0xf9 0x01>;
			sustainable-power = <0x41c>;

			trips {

				trip-point0 {
					temperature = <0x15f90>;
					hysteresis = <0x7d0>;
					type = "passive";
					phandle = <0xfa>;
				};

				trip-point1 {
					temperature = <0x17318>;
					hysteresis = <0x7d0>;
					type = "passive";
					phandle = <0xfb>;
				};

				cpu-crit {
					temperature = <0x1adb0>;
					hysteresis = <0x3e8>;
					type = "critical";
				};
			};

			cooling-maps {

				map0 {
					trip = <0xfa>;
					cooling-device = <0x19 0xffffffff 0xffffffff 0x1a 0xffffffff 0xffffffff 0x1b 0xffffffff 0xffffffff 0x1c 0xffffffff 0xffffffff 0x1d 0xffffffff 0xffffffff 0x1e 0xffffffff 0xffffffff>;
				};

				map1 {
					trip = <0xfb>;
					cooling-device = <0x19 0xffffffff 0xffffffff 0x1a 0xffffffff 0xffffffff 0x1b 0xffffffff 0xffffffff 0x1c 0xffffffff 0xffffffff 0x1d 0xffffffff 0xffffffff 0x1e 0xffffffff 0xffffffff>;
				};
			};
		};

		cpu1-thermal {
			polling-delay-passive = <0xfa>;
			polling-delay = <0x00>;
			thermal-sensors = <0xf9 0x02>;
			sustainable-power = <0x41c>;

			trips {

				trip-point0 {
					temperature = <0x15f90>;
					hysteresis = <0x7d0>;
					type = "passive";
					phandle = <0xfc>;
				};

				trip-point1 {
					temperature = <0x17318>;
					hysteresis = <0x7d0>;
					type = "passive";
					phandle = <0xfd>;
				};

				cpu-crit {
					temperature = <0x1adb0>;
					hysteresis = <0x3e8>;
					type = "critical";
				};
			};

			cooling-maps {

				map0 {
					trip = <0xfc>;
					cooling-device = <0x19 0xffffffff 0xffffffff 0x1a 0xffffffff 0xffffffff 0x1b 0xffffffff 0xffffffff 0x1c 0xffffffff 0xffffffff 0x1d 0xffffffff 0xffffffff 0x1e 0xffffffff 0xffffffff>;
				};

				map1 {
					trip = <0xfd>;
					cooling-device = <0x19 0xffffffff 0xffffffff 0x1a 0xffffffff 0xffffffff 0x1b 0xffffffff 0xffffffff 0x1c 0xffffffff 0xffffffff 0x1d 0xffffffff 0xffffffff 0x1e 0xffffffff 0xffffffff>;
				};
			};
		};

		cpu2-thermal {
			polling-delay-passive = <0xfa>;
			polling-delay = <0x00>;
			thermal-sensors = <0xf9 0x03>;
			sustainable-power = <0x41c>;

			trips {

				trip-point0 {
					temperature = <0x15f90>;
					hysteresis = <0x7d0>;
					type = "passive";
					phandle = <0xfe>;
				};

				trip-point1 {
					temperature = <0x17318>;
					hysteresis = <0x7d0>;
					type = "passive";
					phandle = <0xff>;
				};

				cpu-crit {
					temperature = <0x1adb0>;
					hysteresis = <0x3e8>;
					type = "critical";
				};
			};

			cooling-maps {

				map0 {
					trip = <0xfe>;
					cooling-device = <0x19 0xffffffff 0xffffffff 0x1a 0xffffffff 0xffffffff 0x1b 0xffffffff 0xffffffff 0x1c 0xffffffff 0xffffffff 0x1d 0xffffffff 0xffffffff 0x1e 0xffffffff 0xffffffff>;
				};

				map1 {
					trip = <0xff>;
					cooling-device = <0x19 0xffffffff 0xffffffff 0x1a 0xffffffff 0xffffffff 0x1b 0xffffffff 0xffffffff 0x1c 0xffffffff 0xffffffff 0x1d 0xffffffff 0xffffffff 0x1e 0xffffffff 0xffffffff>;
				};
			};
		};

		cpu3-thermal {
			polling-delay-passive = <0xfa>;
			polling-delay = <0x00>;
			thermal-sensors = <0xf9 0x04>;
			sustainable-power = <0x41c>;

			trips {

				trip-point0 {
					temperature = <0x15f90>;
					hysteresis = <0x7d0>;
					type = "passive";
					phandle = <0x100>;
				};

				trip-point1 {
					temperature = <0x17318>;
					hysteresis = <0x7d0>;
					type = "passive";
					phandle = <0x101>;
				};

				cpu-crit {
					temperature = <0x1adb0>;
					hysteresis = <0x3e8>;
					type = "critical";
				};
			};

			cooling-maps {

				map0 {
					trip = <0x100>;
					cooling-device = <0x19 0xffffffff 0xffffffff 0x1a 0xffffffff 0xffffffff 0x1b 0xffffffff 0xffffffff 0x1c 0xffffffff 0xffffffff 0x1d 0xffffffff 0xffffffff 0x1e 0xffffffff 0xffffffff>;
				};

				map1 {
					trip = <0x101>;
					cooling-device = <0x19 0xffffffff 0xffffffff 0x1a 0xffffffff 0xffffffff 0x1b 0xffffffff 0xffffffff 0x1c 0xffffffff 0xffffffff 0x1d 0xffffffff 0xffffffff 0x1e 0xffffffff 0xffffffff>;
				};
			};
		};

		cpu4-thermal {
			polling-delay-passive = <0xfa>;
			polling-delay = <0x00>;
			thermal-sensors = <0xf9 0x05>;
			sustainable-power = <0x41c>;

			trips {

				trip-point0 {
					temperature = <0x15f90>;
					hysteresis = <0x7d0>;
					type = "passive";
					phandle = <0x102>;
				};

				trip-point1 {
					temperature = <0x17318>;
					hysteresis = <0x7d0>;
					type = "passive";
					phandle = <0x103>;
				};

				cpu-crit {
					temperature = <0x1adb0>;
					hysteresis = <0x3e8>;
					type = "critical";
				};
			};

			cooling-maps {

				map0 {
					trip = <0x102>;
					cooling-device = <0x19 0xffffffff 0xffffffff 0x1a 0xffffffff 0xffffffff 0x1b 0xffffffff 0xffffffff 0x1c 0xffffffff 0xffffffff 0x1d 0xffffffff 0xffffffff 0x1e 0xffffffff 0xffffffff>;
				};

				map1 {
					trip = <0x103>;
					cooling-device = <0x19 0xffffffff 0xffffffff 0x1a 0xffffffff 0xffffffff 0x1b 0xffffffff 0xffffffff 0x1c 0xffffffff 0xffffffff 0x1d 0xffffffff 0xffffffff 0x1e 0xffffffff 0xffffffff>;
				};
			};
		};

		cpu5-thermal {
			polling-delay-passive = <0xfa>;
			polling-delay = <0x00>;
			thermal-sensors = <0xf9 0x06>;
			sustainable-power = <0x41c>;

			trips {

				trip-point0 {
					temperature = <0x15f90>;
					hysteresis = <0x7d0>;
					type = "passive";
					phandle = <0x104>;
				};

				trip-point1 {
					temperature = <0x17318>;
					hysteresis = <0x7d0>;
					type = "passive";
					phandle = <0x105>;
				};

				cpu-crit {
					temperature = <0x1adb0>;
					hysteresis = <0x3e8>;
					type = "critical";
				};
			};

			cooling-maps {

				map0 {
					trip = <0x104>;
					cooling-device = <0x19 0xffffffff 0xffffffff 0x1a 0xffffffff 0xffffffff 0x1b 0xffffffff 0xffffffff 0x1c 0xffffffff 0xffffffff 0x1d 0xffffffff 0xffffffff 0x1e 0xffffffff 0xffffffff>;
				};

				map1 {
					trip = <0x105>;
					cooling-device = <0x19 0xffffffff 0xffffffff 0x1a 0xffffffff 0xffffffff 0x1b 0xffffffff 0xffffffff 0x1c 0xffffffff 0xffffffff 0x1d 0xffffffff 0xffffffff 0x1e 0xffffffff 0xffffffff>;
				};
			};
		};

		cpu6-thermal {
			polling-delay-passive = <0xfa>;
			polling-delay = <0x00>;
			thermal-sensors = <0xf9 0x09>;
			sustainable-power = <0x591>;

			trips {

				trip-point0 {
					temperature = <0x15f90>;
					hysteresis = <0x7d0>;
					type = "passive";
					phandle = <0x106>;
				};

				trip-point1 {
					temperature = <0x17318>;
					hysteresis = <0x7d0>;
					type = "passive";
					phandle = <0x107>;
				};

				cpu-crit {
					temperature = <0x1adb0>;
					hysteresis = <0x3e8>;
					type = "critical";
				};
			};

			cooling-maps {

				map0 {
					trip = <0x106>;
					cooling-device = <0x1f 0xffffffff 0xffffffff 0x20 0xffffffff 0xffffffff>;
				};

				map1 {
					trip = <0x107>;
					cooling-device = <0x1f 0xffffffff 0xffffffff 0x20 0xffffffff 0xffffffff>;
				};
			};
		};

		cpu7-thermal {
			polling-delay-passive = <0xfa>;
			polling-delay = <0x00>;
			thermal-sensors = <0xf9 0x0a>;
			sustainable-power = <0x591>;

			trips {

				trip-point0 {
					temperature = <0x15f90>;
					hysteresis = <0x7d0>;
					type = "passive";
					phandle = <0x108>;
				};

				trip-point1 {
					temperature = <0x17318>;
					hysteresis = <0x7d0>;
					type = "passive";
					phandle = <0x109>;
				};

				cpu-crit {
					temperature = <0x1adb0>;
					hysteresis = <0x3e8>;
					type = "critical";
				};
			};

			cooling-maps {

				map0 {
					trip = <0x108>;
					cooling-device = <0x1f 0xffffffff 0xffffffff 0x20 0xffffffff 0xffffffff>;
				};

				map1 {
					trip = <0x109>;
					cooling-device = <0x1f 0xffffffff 0xffffffff 0x20 0xffffffff 0xffffffff>;
				};
			};
		};

		cpu8-thermal {
			polling-delay-passive = <0xfa>;
			polling-delay = <0x00>;
			thermal-sensors = <0xf9 0x0b>;
			sustainable-power = <0x591>;

			trips {

				trip-point0 {
					temperature = <0x15f90>;
					hysteresis = <0x7d0>;
					type = "passive";
					phandle = <0x10a>;
				};

				trip-point1 {
					temperature = <0x17318>;
					hysteresis = <0x7d0>;
					type = "passive";
					phandle = <0x10b>;
				};

				cpu-crit {
					temperature = <0x1adb0>;
					hysteresis = <0x3e8>;
					type = "critical";
				};
			};

			cooling-maps {

				map0 {
					trip = <0x10a>;
					cooling-device = <0x1f 0xffffffff 0xffffffff 0x20 0xffffffff 0xffffffff>;
				};

				map1 {
					trip = <0x10b>;
					cooling-device = <0x1f 0xffffffff 0xffffffff 0x20 0xffffffff 0xffffffff>;
				};
			};
		};

		cpu9-thermal {
			polling-delay-passive = <0xfa>;
			polling-delay = <0x00>;
			thermal-sensors = <0xf9 0x0c>;
			sustainable-power = <0x591>;

			trips {

				trip-point0 {
					temperature = <0x15f90>;
					hysteresis = <0x7d0>;
					type = "passive";
					phandle = <0x10c>;
				};

				trip-point1 {
					temperature = <0x17318>;
					hysteresis = <0x7d0>;
					type = "passive";
					phandle = <0x10d>;
				};

				cpu-crit {
					temperature = <0x1adb0>;
					hysteresis = <0x3e8>;
					type = "critical";
				};
			};

			cooling-maps {

				map0 {
					trip = <0x10c>;
					cooling-device = <0x1f 0xffffffff 0xffffffff 0x20 0xffffffff 0xffffffff>;
				};

				map1 {
					trip = <0x10d>;
					cooling-device = <0x1f 0xffffffff 0xffffffff 0x20 0xffffffff 0xffffffff>;
				};
			};
		};

		aoss0-thermal {
			polling-delay-passive = <0xfa>;
			polling-delay = <0x00>;
			thermal-sensors = <0xf9 0x00>;

			trips {

				trip-point0 {
					temperature = <0x15f90>;
					hysteresis = <0x7d0>;
					type = "hot";
				};

				aoss0-crit {
					temperature = <0x1adb0>;
					hysteresis = <0x7d0>;
					type = "critical";
				};
			};
		};

		cpuss0-thermal {
			polling-delay-passive = <0xfa>;
			polling-delay = <0x00>;
			thermal-sensors = <0xf9 0x07>;

			trips {

				trip-point0 {
					temperature = <0x15f90>;
					hysteresis = <0x7d0>;
					type = "hot";
				};

				cluster0-crit {
					temperature = <0x1adb0>;
					hysteresis = <0x7d0>;
					type = "critical";
				};
			};
		};

		cpuss1-thermal {
			polling-delay-passive = <0xfa>;
			polling-delay = <0x00>;
			thermal-sensors = <0xf9 0x08>;

			trips {

				trip-point0 {
					temperature = <0x15f90>;
					hysteresis = <0x7d0>;
					type = "hot";
				};

				cluster0-crit {
					temperature = <0x1adb0>;
					hysteresis = <0x7d0>;
					type = "critical";
				};
			};
		};

		gpuss0-thermal {
			polling-delay-passive = <0xfa>;
			polling-delay = <0x00>;
			thermal-sensors = <0xf9 0x0d>;

			trips {

				trip-point0 {
					temperature = <0x17318>;
					hysteresis = <0x7d0>;
					type = "passive";
					phandle = <0x10e>;
				};

				gpuss0-crit {
					temperature = <0x1adb0>;
					hysteresis = <0x7d0>;
					type = "critical";
				};
			};

			cooling-maps {

				map0 {
					trip = <0x10e>;
					cooling-device = <0x10f 0xffffffff 0xffffffff>;
				};
			};
		};

		gpuss1-thermal {
			polling-delay-passive = <0xfa>;
			polling-delay = <0x00>;
			thermal-sensors = <0xf9 0x0e>;

			trips {

				trip-point0 {
					temperature = <0x17318>;
					hysteresis = <0x7d0>;
					type = "passive";
					phandle = <0x110>;
				};

				gpuss1-crit {
					temperature = <0x1adb0>;
					hysteresis = <0x7d0>;
					type = "critical";
				};
			};

			cooling-maps {

				map0 {
					trip = <0x110>;
					cooling-device = <0x10f 0xffffffff 0xffffffff>;
				};
			};
		};

		aoss1-thermal {
			polling-delay-passive = <0xfa>;
			polling-delay = <0x00>;
			thermal-sensors = <0x111 0x00>;

			trips {

				trip-point0 {
					temperature = <0x15f90>;
					hysteresis = <0x7d0>;
					type = "hot";
				};

				aoss1-crit {
					temperature = <0x1adb0>;
					hysteresis = <0x7d0>;
					type = "critical";
				};
			};
		};

		cwlan-thermal {
			polling-delay-passive = <0xfa>;
			polling-delay = <0x00>;
			thermal-sensors = <0x111 0x01>;

			trips {

				trip-point0 {
					temperature = <0x15f90>;
					hysteresis = <0x7d0>;
					type = "hot";
				};

				cwlan-crit {
					temperature = <0x1adb0>;
					hysteresis = <0x7d0>;
					type = "critical";
				};
			};
		};

		audio-thermal {
			polling-delay-passive = <0xfa>;
			polling-delay = <0x00>;
			thermal-sensors = <0x111 0x02>;

			trips {

				trip-point0 {
					temperature = <0x15f90>;
					hysteresis = <0x7d0>;
					type = "hot";
				};

				audio-crit {
					temperature = <0x1adb0>;
					hysteresis = <0x7d0>;
					type = "critical";
				};
			};
		};

		ddr-thermal {
			polling-delay-passive = <0xfa>;
			polling-delay = <0x00>;
			thermal-sensors = <0x111 0x03>;

			trips {

				trip-point0 {
					temperature = <0x15f90>;
					hysteresis = <0x7d0>;
					type = "hot";
				};

				ddr-crit {
					temperature = <0x1adb0>;
					hysteresis = <0x7d0>;
					type = "critical";
				};
			};
		};

		q6-hvx-thermal {
			polling-delay-passive = <0xfa>;
			polling-delay = <0x00>;
			thermal-sensors = <0x111 0x04>;

			trips {

				trip-point0 {
					temperature = <0x15f90>;
					hysteresis = <0x7d0>;
					type = "hot";
				};

				q6-hvx-crit {
					temperature = <0x1adb0>;
					hysteresis = <0x7d0>;
					type = "critical";
				};
			};
		};

		camera-thermal {
			polling-delay-passive = <0xfa>;
			polling-delay = <0x00>;
			thermal-sensors = <0x111 0x05>;

			trips {

				trip-point0 {
					temperature = <0x15f90>;
					hysteresis = <0x7d0>;
					type = "hot";
				};

				camera-crit {
					temperature = <0x1adb0>;
					hysteresis = <0x7d0>;
					type = "critical";
				};
			};
		};

		mdm-core-thermal {
			polling-delay-passive = <0xfa>;
			polling-delay = <0x00>;
			thermal-sensors = <0x111 0x06>;

			trips {

				trip-point0 {
					temperature = <0x15f90>;
					hysteresis = <0x7d0>;
					type = "hot";
				};

				mdm-crit {
					temperature = <0x1adb0>;
					hysteresis = <0x7d0>;
					type = "critical";
				};
			};
		};

		mdm-dsp-thermal {
			polling-delay-passive = <0xfa>;
			polling-delay = <0x00>;
			thermal-sensors = <0x111 0x07>;

			trips {

				trip-point0 {
					temperature = <0x15f90>;
					hysteresis = <0x7d0>;
					type = "hot";
				};

				mdm-dsp-crit {
					temperature = <0x1adb0>;
					hysteresis = <0x7d0>;
					type = "critical";
				};
			};
		};

		npu-thermal {
			polling-delay-passive = <0xfa>;
			polling-delay = <0x00>;
			thermal-sensors = <0x111 0x08>;

			trips {

				trip-point0 {
					temperature = <0x15f90>;
					hysteresis = <0x7d0>;
					type = "hot";
				};

				npu-crit {
					temperature = <0x1adb0>;
					hysteresis = <0x7d0>;
					type = "critical";
				};
			};
		};

		video-thermal {
			polling-delay-passive = <0xfa>;
			polling-delay = <0x00>;
			thermal-sensors = <0x111 0x09>;

			trips {

				trip-point0 {
					temperature = <0x15f90>;
					hysteresis = <0x7d0>;
					type = "hot";
				};

				video-crit {
					temperature = <0x1adb0>;
					hysteresis = <0x7d0>;
					type = "critical";
				};
			};
		};

		pm6150-thermal {
			polling-delay-passive = <0x64>;
			polling-delay = <0x00>;
			thermal-sensors = <0x112>;

			trips {

				trip0 {
					temperature = <0x17318>;
					hysteresis = <0x00>;
					type = "passive";
				};

				crit {
					temperature = <0x1c138>;
					hysteresis = <0x00>;
					type = "critical";
				};
			};
		};

		pm6150l-thermal {
			polling-delay-passive = <0x00>;
			polling-delay = <0x00>;
			thermal-sensors = <0x113>;

			trips {

				trip0 {
					temperature = <0x17318>;
					hysteresis = <0x00>;
					type = "passive";
				};

				trip1 {
					temperature = <0x1c138>;
					hysteresis = <0x00>;
					type = "hot";
				};

				trip2 {
					temperature = <0x1e848>;
					hysteresis = <0x00>;
					type = "critical";
				};
			};
		};
	};

	timer {
		compatible = "arm,armv8-timer";
		interrupts = <0x01 0x01 0x08 0x01 0x02 0x08 0x01 0x03 0x08 0x01 0x00 0x08>;
	};

	gpio-keys {
		compatible = "gpio-keys";
		pinctrl-names = "default";
		pinctrl-0 = <0x114 0x115>;

		vol-up {
			label = "Volume up";
			gpios = <0xd6 0x08 0x01>;
			linux,code = <0x73>;
			debounce-interval = <0x0f>;
			linux,can-disable;
			wakeup-source;
		};

		event-hall-sensor {
			label = "Hall Effect Sensor";
			gpios = <0xd5 0x0a 0x01>;
			linux,input-type = <0x05>;
			linux,code = <0x00>;
			debounce-interval = <0x0f>;
			linux,can-disable;
			wakeup-source;
		};
	};

	vibrator {
		compatible = "gpio-vibrator";
		enable-gpios = <0x48 0x39 0x00>;
		pinctrl-names = "default";
	};

	audio-codec {
		compatible = "qcom,wcd9380-codec";
		pinctrl-names = "default";
		pinctrl-0 = <0x116>;
		qcom,micbias1-microvolt = <0x1b7740>;
		qcom,micbias2-microvolt = <0x1b7740>;
		qcom,micbias3-microvolt = <0x1b7740>;
		qcom,micbias4-microvolt = <0x1b7740>;
		qcom,mbhc-buttons-vthreshold-microvolt = <0x124f8 0x249f0 0x39dc8 0x7a120 0x7a120 0x7a120 0x7a120 0x7a120>;
		qcom,mbhc-headset-vthreshold-microvolt = <0x19f0a0>;
		qcom,mbhc-headphone-vthreshold-microvolt = <0xc350>;
		qcom,rx-device = <0x117>;
		qcom,tx-device = <0x118>;
		reset-gpios = <0x48 0x3a 0x01>;
		vdd-buck-supply = <0x119>;
		vdd-rxtx-supply = <0x4a>;
		vdd-io-supply = <0x4a>;
		vdd-mic-bias-supply = <0x11a>;
		#sound-dai-cells = <0x01>;
		phandle = <0xf2>;
	};
};
